VERSION ""

NS_ :

BS_:

BU_: mLEDR mLEDL TLR TLL RLR RLL HLR HLL DASCU CGW BCM

BO_ 656 DASCU_HLL_Object: 64 DASCU
 SG_ DAS_LeftObj_10_Z_2_Val : 337|7@1+ (1,0) [0|81] ""  mLEDL
 SG_ DAS_LeftObj_3_Y_1_Val : 88|9@1+ (1,0) [0|321] ""  mLEDL
 SG_ DAS_ADBLeftLED8_Req : 11|1@1+ (1,0) [0|1] ""  HLL
 SG_ DAS_ADBLeftLED11_Req : 14|1@1+ (1,0) [0|1] ""  HLL
 SG_ DAS_LeftObj_3_Y_2_Val : 104|9@1+ (1,0) [0|321] ""  mLEDL
 SG_ DAS_ADBLeftLED6_Req : 9|1@1+ (1,0) [0|1] ""  HLL
 SG_ DAS_LeftObj_6_Y_1_Val : 184|9@1+ (1,0) [0|321] ""  mLEDL
 SG_ DAS_LeftObj_5_Z_2_Val : 177|7@1+ (1,0) [0|81] ""  mLEDL
 SG_ DAS_LeftObj_9_Z_2_Val : 305|7@1+ (1,0) [0|81] ""  mLEDL
 SG_ DAS_LeftObj_5_Y_1_Val : 152|9@1+ (1,0) [0|321] ""  mLEDL
 SG_ DAS_LeftObj_1_Y_2_Val : 40|9@1+ (1,0) [0|321] ""  mLEDL
 SG_ DAS_LeftObj_2_Z_1_Val : 65|7@1+ (1,0) [0|81] ""  mLEDL
 SG_ DAS_LeftObj_1_Z_2_Val : 49|7@1+ (1,0) [0|81] ""  mLEDL
 SG_ DAS_ADBLeftLED13_Req : 16|1@1+ (1,0) [0|1] ""  HLL
 SG_ DAS_LeftObj_9_Y_2_Val : 296|9@1+ (1,0) [0|321] ""  mLEDL
 SG_ DAS_LeftObj_6_Z_2_Val : 209|7@1+ (1,0) [0|81] ""  mLEDL
 SG_ DAS_LeftObj_7_Z_2_Val : 241|7@1+ (1,0) [0|81] ""  mLEDL
 SG_ DAS_LeftObj_6_Z_1_Val : 193|7@1+ (1,0) [0|81] ""  mLEDL
 SG_ DAS_ADBLeftLED14_Req : 17|1@1+ (1,0) [0|1] ""  HLL
 SG_ DAS_LeftObj_5_Y_2_Val : 168|9@1+ (1,0) [0|321] ""  mLEDL
 SG_ DAS_LeftObj_7_Z_1_Val : 225|7@1+ (1,0) [0|81] ""  mLEDL
 SG_ DAS_ADBLeftLED2_Req : 5|1@1+ (1,0) [0|1] ""  HLL
 SG_ DAS_LeftObj_6_Y_2_Val : 200|9@1+ (1,0) [0|321] ""  mLEDL
 SG_ DAS_LeftObj_3_Z_2_Val : 113|7@1+ (1,0) [0|81] ""  mLEDL
 SG_ DAS_ADBLeftLED3_Req : 6|1@1+ (1,0) [0|1] ""  HLL
 SG_ DAS_ADBLeftLED10_Req : 13|1@1+ (1,0) [0|1] ""  HLL
 SG_ DAS_LeftObj_10_Z_1_Val : 321|7@1+ (1,0) [0|81] ""  mLEDL
 SG_ DAS_LeftObj_8_Z_2_Val : 273|7@1+ (1,0) [0|81] ""  mLEDL
 SG_ DAS_ADBLeftLED15_Req : 18|1@1+ (1,0) [0|1] ""  HLL
 SG_ DAS_LeftObj_4_Z_2_Val : 145|7@1+ (1,0) [0|81] ""  mLEDL
 SG_ DAS_ADBLeftLED1_Req : 4|1@1+ (1,0) [0|1] ""  HLL
 SG_ DAS_ADBLeftLED16_Req : 19|1@1+ (1,0) [0|1] ""  HLL
 SG_ DAS_LeftObj_7_Y_2_Val : 232|9@1+ (1,0) [0|321] ""  mLEDL
 SG_ DAS_LeftObj_2_Y_2_Val : 72|9@1+ (1,0) [0|321] ""  mLEDL
 SG_ DAS_LeftObj_10_Y_2_Val : 328|9@1+ (1,0) [0|321] ""  mLEDL
 SG_ DAS_LeftObj_8_Z_1_Val : 257|7@1+ (1,0) [0|81] ""  mLEDL
 SG_ DAS_LeftObj_9_Y_1_Val : 280|9@1+ (1,0) [0|321] ""  mLEDL
 SG_ DAS_LeftObj_8_Y_2_Val : 264|9@1+ (1,0) [0|321] ""  mLEDL
 SG_ DAS_LeftObj_4_Z_1_Val : 129|7@1+ (1,0) [0|81] ""  mLEDL
 SG_ DAS_LeftObj_2_Z_2_Val : 81|7@1+ (1,0) [0|81] ""  mLEDL
 SG_ DAS_LeftObj_8_Y_1_Val : 248|9@1+ (1,0) [0|321] ""  mLEDL
 SG_ DAS_LeftObj_1_Y_1_Val : 24|9@1+ (1,0) [0|511] ""  mLEDL
 SG_ DAS_LeftObj_4_Y_2_Val : 136|9@1+ (1,0) [0|321] ""  mLEDL
 SG_ DAS_LeftObj_4_Y_1_Val : 120|9@1+ (1,0) [0|321] ""  mLEDL
 SG_ DAS_ADBLeftLED5_Req : 8|1@1+ (1,0) [0|1] ""  HLL
 SG_ DAS_ADBLeftLED7_Req : 10|1@1+ (1,0) [0|1] ""  HLL
 SG_ DAS_LeftObj_5_Z_1_Val : 161|7@1+ (1,0) [0|81] ""  mLEDL
 SG_ DAS_LeftObj_10_Y_1_Val : 312|9@1+ (1,0) [0|321] ""  mLEDL
 SG_ DAS_ADBLeftLED12_Req : 15|1@1+ (1,0) [0|1] ""  HLL
 SG_ DAS_HLL_Object_RC : 379|4@1+ (1,0) [0|15] ""  mLEDL,HLL
 SG_ DAS_ADBLeftLED18_Req : 21|1@1+ (1,0) [0|1] ""  HLL
 SG_ DAS_LeftObj_3_Z_1_Val : 97|7@1+ (1,0) [0|81] ""  mLEDL
 SG_ DAS_LeftObj_2_Y_1_Val : 56|9@1+ (1,0) [0|321] ""  mLEDL
 SG_ DAS_ADBLeftLED17_Req : 20|1@1+ (1,0) [0|1] ""  HLL
 SG_ DAS_LeftObj_9_Z_1_Val : 289|7@1+ (1,0) [0|81] ""  mLEDL
 SG_ DAS_HLL_Object_CS : 384|8@1+ (1,0) [0|255] ""  mLEDL,HLL
 SG_ DAS_LeftObj_1_Z_1_Val : 33|7@1+ (1,0) [0|81] ""  mLEDL
 SG_ DAS_ADBLeftLED9_Req : 12|1@1+ (1,0) [0|1] ""  HLL
 SG_ DAS_ADBLeftLED4_Req : 7|1@1+ (1,0) [0|1] ""  HLL
 SG_ DAS_LeftObj_7_Y_1_Val : 216|9@1+ (1,0) [0|321] ""  mLEDL

BO_ 785 CCU_Stat1: 8 CGW
 SG_ CCU_AirDirectionFR_Foot_Stat : 29|1@1+ (1,0) [0|1] "" Vector__XXX
 SG_ CCU_AirDirectionFR_Face_Stat : 28|1@1+ (1,0) [0|1] "" Vector__XXX
 SG_ CCU_AirDirectionFR_Def_Stat : 27|1@1+ (1,0) [0|1] "" Vector__XXX
 SG_ CCU_AirDirectionFL_Foot_Stat : 26|1@1+ (1,0) [0|1] "" Vector__XXX
 SG_ CCU_AirDirectionFL_Face_Stat : 25|1@1+ (1,0) [0|1] "" Vector__XXX
 SG_ CCU_AirDirectionRL_Foot_Stat : 15|1@1+ (1,0) [0|1] "" Vector__XXX
 SG_ CCU_ModeRL_Stat : 4|2@1+ (1,0) [0|2] "" Vector__XXX
 SG_ CCU_AutoModeRR_Stat : 19|3@1+ (1,0) [0|5] "" Vector__XXX
 SG_ CCU_AutoModeFR_Stat : 11|3@1+ (1,0) [0|5] "" Vector__XXX
 SG_ CCU_AirDirectionRR_Face_Stat : 22|1@1+ (1,0) [0|1] "" Vector__XXX
 SG_ CCU_ModeRR_Stat : 6|2@1+ (1,0) [0|2] "" Vector__XXX
 SG_ CCU_AirDirectionRR_Foot_Stat : 23|1@1+ (1,0) [0|1] "" Vector__XXX
 SG_ CCU_Recirculation_Stat : 30|2@1+ (1,0) [0|2] "" Vector__XXX
 SG_ CCU_AutoModeRL_Stat : 16|3@1+ (1,0) [0|5] "" Vector__XXX
 SG_ CCU_AirDirectionFL_Def_Stat : 24|1@1+ (1,0) [0|1] "" Vector__XXX
 SG_ CCU_AutoModeFL_Stat : 8|3@1+ (1,0) [0|5] "" Vector__XXX
 SG_ CCU_ModeFL_Stat : 0|2@1+ (1,0) [0|2] "" Vector__XXX
 SG_ CCU_ModeFR_Stat : 2|2@1+ (1,0) [0|2] "" Vector__XXX
 SG_ CCU_AirDirectionRL_Face_Stat : 14|1@1+ (1,0) [0|1] "" Vector__XXX
 SG_ CCU_TargetTempFR_Stat : 43|5@1+ (0.5,16) [16|31.5] ""  DASCU
 SG_ CCU_BlowerSpeedRL_Stat : 48|3@1+ (1,0) [0|7] ""  DASCU
 SG_ CCU_BlowerSpeedFR_Stat : 40|3@1+ (1,0) [0|7] ""  DASCU
 SG_ CCU_TargetTempFL_Stat : 35|5@1+ (0.5,16) [16|31.5] ""  DASCU
 SG_ CCU_TargetTempRL_Stat : 59|5@1+ (0.5,16) [16|31.5] ""  DASCU
 SG_ CCU_BlowerSpeedFL_Stat : 32|3@1+ (1,0) [0|7] ""  DASCU
 SG_ CCU_TargetTempRR_Stat : 51|5@1+ (0.5,16) [16|31.5] ""  DASCU
 SG_ CCU_BlowerSpeedRR_Stat : 56|3@1+ (1,0) [0|7] ""  DASCU

BO_ 560 BCM_EXT_LGT: 8 BCM
 SG_ BCM_TargetLvlALS_Req : 32|8@1+ (1,0) [0|255] ""  HLL,HLR,DASCU
 SG_ BCM_CorneringLight_Req : 12|2@1+ (1,0) [0|3] ""  HLL,HLR
 SG_ BCM_RearFogLightCntrl_Req : 5|1@1+ (1,0) [0|1] ""  TLR,RLL,RLR,TLL
 SG_ BCM_PositionLightRear_Req : 1|1@1+ (1,0) [0|1] ""  TLL,RLL,RLR,TLR
 SG_ BCM_HighBeam_Req : 10|2@1+ (1,0) [0|3] ""  DASCU,mLEDL,HLR,HLL,mLEDR
 SG_ BCM_ELSStat_Req : 9|1@1+ (1,0) [0|1] ""  HLR,HLL,mLEDL,RLR,RLL,TLR,TLL,mLEDR
 SG_ BCM_ReverseLightCntrl_Req : 7|1@1+ (1,0) [0|1] ""  RLL,RLR,TLL,TLR
 SG_ BCM_EXT_LGT_RC : 52|4@1+ (1,0) [0|15] ""  TLR,mLEDR,TLL,mLEDL,HLR,RLR,HLL,DASCU,RLL
 SG_ BCM_CourtesyLightEffect_Req : 14|2@1+ (1,0) [0|2] ""  RLL,RLR,HLL,TLR,TLL,HLR
 SG_ BCM_TurnIndL_Req : 2|1@1+ (1,0) [0|1] ""  DASCU,RLL,HLL,TLL
 SG_ BCM_TrafficSide_Req : 8|1@1+ (1,0) [0|1] ""  HLL,HLR,mLEDR,mLEDL
 SG_ BCM_CourtesyProjAnimation_Req : 16|2@1+ (1,0) [0|3] ""  mLEDL,mLEDR
 SG_ BCM_EXT_LGT_CS : 56|8@1+ (1,0) [0|255] ""  TLL,RLL,mLEDR,RLR,mLEDL,DASCU,TLR,HLR,HLL
 SG_ BCM_DayRunningLight_Req : 4|1@1+ (1,0) [0|1] ""  HLL,HLR
 SG_ BCM_LowBeam_Req : 18|3@1+ (1,0) [0|4] ""  HLL,mLEDR,mLEDL,HLR
 SG_ BCM_PositionLightFront_Req : 0|1@1+ (1,0) [0|1] ""  HLR,HLL
 SG_ BCM_SteeringWheelAngle_Val : 24|8@1+ (1,0) [0|40] "°"  mLEDL,mLEDR
 SG_ BCM_BrakeLightCntrl_Req : 6|1@1+ (1,0) [0|1] ""  RLR,TLR,TLL,RLL
 SG_ BCM_TurnIndR_Req : 3|1@1+ (1,0) [0|1] ""  DASCU,TLR,HLR,RLR
 SG_ BCM_MLIA_Start_Req : 23|1@1+ (1,0) [0|1] ""  DASCU
 SG_ BCM_Proj_Start_Req : 21|2@1+ (1,0) [0|1] ""  DASCU

BO_ 1306 VEH_VIN: 8 CGW
 SG_ VIN_Char13 m1 : 48|8@1+ (1,0) [0|255] "" Vector__XXX
 SG_ VIN_Char1 m0 : 8|8@1+ (1,0) [0|255] "" Vector__XXX
 SG_ VIN_Char3 m0 : 24|8@1+ (1,0) [0|255] "" Vector__XXX
 SG_ VIN_Char17 m2 : 24|8@1+ (1,0) [0|255] "" Vector__XXX
 SG_ VIN_Char7 m0 : 56|8@1+ (1,0) [0|255] "" Vector__XXX
 SG_ VIN_Char10 m1 : 24|8@1+ (1,0) [0|255] "" Vector__XXX
 SG_ VIN_Char12 m1 : 40|8@1+ (1,0) [0|255] "" Vector__XXX
 SG_ VIN_Addressing M : 0|2@1+ (1,0) [0|2] "" Vector__XXX
 SG_ VIN_Char5 m0 : 40|8@1+ (1,0) [0|255] "" Vector__XXX
 SG_ VIN_Char9 m1 : 16|8@1+ (1,0) [0|255] "" Vector__XXX
 SG_ VIN_Char2 m0 : 16|8@1+ (1,0) [0|255] "" Vector__XXX
 SG_ VIN_Char4 m0 : 32|8@1+ (1,0) [0|255] "" Vector__XXX
 SG_ VIN_Char15 m2 : 8|8@1+ (1,0) [0|255] "" Vector__XXX
 SG_ VIN_Char6 m0 : 48|8@1+ (1,0) [0|255] "" Vector__XXX
 SG_ VIN_Char8 m1 : 8|8@1+ (1,0) [0|255] "" Vector__XXX
 SG_ VIN_Char11 m1 : 32|8@1+ (1,0) [0|255] "" Vector__XXX
 SG_ VIN_Char14 m1 : 56|8@1+ (1,0) [0|255] "" Vector__XXX
 SG_ VIN_Char16 m2 : 16|8@1+ (1,0) [0|255] "" Vector__XXX

BO_ 1980 Diag_To_ERAG: 8 DASCU
 SG_ Diag_To_ERAG_Sig : 7|64@0+ (1,0) [0|1.84467440737096E+019] ""  CGW

BO_ 2005 Diag_To_DASCU: 8 CGW
 SG_ Diag_To_DASCU_Sig : 7|64@0+ (1,0) [0|1.84467440737096E+019] ""  DASCU

BO_ 1964 Diag_From_ERAG: 8 CGW
 SG_ Diag_From_ERAG_Sig : 7|64@0+ (1,0) [0|1.84467440737096E+019] ""  DASCU

BO_ 1989 Diag_From_DASCU: 8 DASCU
 SG_ Diag_From_DASCU_Sig : 7|64@0+ (1,0) [0|1.84467440737096E+019] ""  CGW

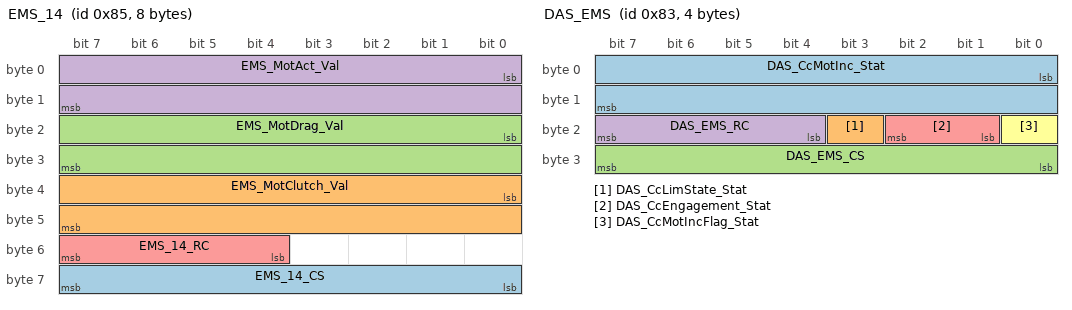
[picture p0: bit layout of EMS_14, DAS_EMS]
BO_ 133 EMS_14: 8 CGW
 SG_ EMS_14_CS : 56|8@1+ (1,0) [0|255] ""  DASCU
 SG_ EMS_MotClutch_Val : 32|16@1+ (1,-30000) [-30000|30000] "Nm"  DASCU
 SG_ EMS_MotDrag_Val : 16|16@1+ (1,-30000) [-30000|30000] "Nm"  DASCU
 SG_ EMS_MotAct_Val : 0|16@1+ (1,-30000) [-30000|30000] "Nm"  DASCU
 SG_ EMS_14_RC : 52|4@1+ (1,0) [0|15] ""  DASCU

BO_ 131 DAS_EMS: 4 DASCU
 SG_ DAS_CcMotInc_Stat : 0|16@1+ (1,-30000) [-30000|30000] ""  CGW
 SG_ DAS_CcLimState_Stat : 19|1@1+ (1,0) [0|1] ""  CGW
 SG_ DAS_EMS_CS : 24|8@1+ (1,0) [0|255] ""  CGW
 SG_ DAS_EMS_RC : 20|4@1+ (1,0) [0|15] ""  CGW
 SG_ DAS_CcEngagement_Stat : 17|2@1+ (1,0) [0|3] ""  CGW
 SG_ DAS_CcMotIncFlag_Stat : 16|1@1+ (1,0) [0|1] ""  CGW

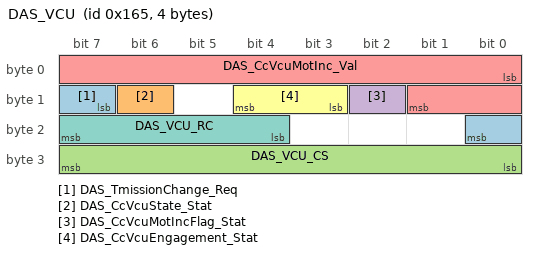
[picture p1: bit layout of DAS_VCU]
BO_ 357 DAS_VCU: 4 DASCU
 SG_ DAS_TmissionChange_Req : 15|2@1+ (1,0) [0|3] ""  CGW
 SG_ DAS_CcVcuState_Stat : 14|1@1+ (1,0) [0|1] ""  CGW
 SG_ DAS_VCU_CS : 24|8@1+ (1,0) [0|255] ""  CGW
 SG_ DAS_CcVcuMotIncFlag_Stat : 10|1@1+ (1,0) [0|1] ""  CGW
 SG_ DAS_CcVcuMotInc_Val : 0|10@1+ (1,0) [0|1000] ""  CGW
 SG_ DAS_CcVcuEngagement_Stat : 11|2@1+ (1,0) [0|3] ""  CGW
 SG_ DAS_VCU_RC : 20|4@1+ (1,0) [0|15] ""  CGW

CM_ SG_ 656 DAS_LeftObj_10_Z_2_Val "Object_10 Vertical  Value_2";
CM_ SG_ 656 DAS_LeftObj_3_Y_1_Val "Object_3 Horizontal Value_1";
CM_ SG_ 656 DAS_ADBLeftLED8_Req "Left_ADB LED#8 Control Signal";
CM_ SG_ 656 DAS_ADBLeftLED11_Req "Left_ADB LED#11 Control Signal";
CM_ SG_ 656 DAS_LeftObj_3_Y_2_Val "Object_3 Horizontal Value_2";
CM_ SG_ 656 DAS_ADBLeftLED6_Req "Left_ADB LED#6 Control Signal";
CM_ SG_ 656 DAS_LeftObj_6_Y_1_Val "Object_6 Horizontal Value_1";
CM_ SG_ 656 DAS_LeftObj_5_Z_2_Val "Object_5 Vertical  Value_2";
CM_ SG_ 656 DAS_LeftObj_9_Z_2_Val "Object_9 Vertical  Value_2";
CM_ SG_ 656 DAS_LeftObj_5_Y_1_Val "Object_5 Horizontal Value_1";
CM_ SG_ 656 DAS_LeftObj_1_Y_2_Val "Object_1 Horizontal Value_2";
CM_ SG_ 656 DAS_LeftObj_2_Z_1_Val "Object_2 Vertical Value_1";
CM_ SG_ 656 DAS_LeftObj_1_Z_2_Val "Object_1 Vertical  Value_2";
CM_ SG_ 656 DAS_ADBLeftLED13_Req "Left_ADB LED#13 Control Signal";
CM_ SG_ 656 DAS_LeftObj_9_Y_2_Val "Object_9 Horizontal Value_2";
CM_ SG_ 656 DAS_LeftObj_6_Z_2_Val "Object_6 Vertical  Value_2";
CM_ SG_ 656 DAS_LeftObj_7_Z_2_Val "Object_7 Vertical  Value_2";
CM_ SG_ 656 DAS_LeftObj_6_Z_1_Val "Object_6 Vertical Value_1";
CM_ SG_ 656 DAS_ADBLeftLED14_Req "Left_ADB LED#14 Control Signal";
CM_ SG_ 656 DAS_LeftObj_5_Y_2_Val "Object_5 Horizontal Value_2";
CM_ SG_ 656 DAS_LeftObj_7_Z_1_Val "Object_7 Vertical Value_1";
CM_ SG_ 656 DAS_ADBLeftLED2_Req "Left_ADB LED#2 Control Signal";
CM_ SG_ 656 DAS_LeftObj_6_Y_2_Val "Object_6 Horizontal Value_2";
CM_ SG_ 656 DAS_LeftObj_3_Z_2_Val "Object_3 Vertical  Value_2";
CM_ SG_ 656 DAS_ADBLeftLED3_Req "Left_ADB LED#3 Control Signal";
CM_ SG_ 656 DAS_ADBLeftLED10_Req "Left_ADB LED#10 Control Signal";
CM_ SG_ 656 DAS_LeftObj_10_Z_1_Val "Object_10 Vertical Value_1";
CM_ SG_ 656 DAS_LeftObj_8_Z_2_Val "Object_8 Vertical  Value_2";
CM_ SG_ 656 DAS_ADBLeftLED15_Req "Left_ADB LED#15 Control Signal";
CM_ SG_ 656 DAS_LeftObj_4_Z_2_Val "Object_4 Vertical  Value_2";
CM_ SG_ 656 DAS_ADBLeftLED1_Req "Left_ADB LED#1 Control Signal";
CM_ SG_ 656 DAS_ADBLeftLED16_Req "Left_ADB LED#16 Control Signal";
CM_ SG_ 656 DAS_LeftObj_7_Y_2_Val "Object_7 Horizontal Value_2";
CM_ SG_ 656 DAS_LeftObj_2_Y_2_Val "Object_2 Horizontal Value_2";
CM_ SG_ 656 DAS_LeftObj_10_Y_2_Val "Object_10 Horizontal Value_2";
CM_ SG_ 656 DAS_LeftObj_8_Z_1_Val "Object_8 Vertical Value_1";
CM_ SG_ 656 DAS_LeftObj_9_Y_1_Val "Object_9 Horizontal Value_1";
CM_ SG_ 656 DAS_LeftObj_8_Y_2_Val "Object_8 Horizontal Value_2";
CM_ SG_ 656 DAS_LeftObj_4_Z_1_Val "Object_4 Vertical Value_1";
CM_ SG_ 656 DAS_LeftObj_2_Z_2_Val "Object_2 Vertical  Value_2";
CM_ SG_ 656 DAS_LeftObj_8_Y_1_Val "Object_8 Horizontal Value_1";
CM_ SG_ 656 DAS_LeftObj_1_Y_1_Val "Object_1 Horizontal Value_1";
CM_ SG_ 656 DAS_LeftObj_4_Y_2_Val "Object_4 Horizontal Value_2";
CM_ SG_ 656 DAS_LeftObj_4_Y_1_Val "Object_4 Horizontal Value_1";
CM_ SG_ 656 DAS_ADBLeftLED5_Req "Left_ADB LED#5 Control Signal";
CM_ SG_ 656 DAS_ADBLeftLED7_Req "Left_ADB LED#7 Control Signal";
CM_ SG_ 656 DAS_LeftObj_5_Z_1_Val "Object_5 Vertical Value_1";
CM_ SG_ 656 DAS_LeftObj_10_Y_1_Val "Object_10 Horizontal Value_1";
CM_ SG_ 656 DAS_ADBLeftLED12_Req "Left_ADB LED#12 Control Signal";
CM_ SG_ 656 DAS_HLL_Object_RC "Rolling Counter [0 - 15]";
CM_ SG_ 656 DAS_ADBLeftLED18_Req "Left_ADB LED#18 Control Signal";
CM_ SG_ 656 DAS_LeftObj_3_Z_1_Val "Object_3 Vertical Value_1";
CM_ SG_ 656 DAS_LeftObj_2_Y_1_Val "Object_2 Horizontal Value_1";
CM_ SG_ 656 DAS_ADBLeftLED17_Req "Left_ADB LED#17 Control Signal";
CM_ SG_ 656 DAS_LeftObj_9_Z_1_Val "Object_9 Vertical Value_1";
CM_ SG_ 656 DAS_HLL_Object_CS "Checksum XOR8 of the data field this message
Checksum computed as per XOR algorithm:
Byte 1 XOR byte 2 .... XOR byte n-1. (n = packet length.)";
CM_ SG_ 656 DAS_LeftObj_1_Z_1_Val "Object_1 Vertical Value_1";
CM_ SG_ 656 DAS_ADBLeftLED9_Req "Left_ADB LED#9 Control Signal";
CM_ SG_ 656 DAS_ADBLeftLED4_Req "Left_ADB LED#4 Control Signal";
CM_ SG_ 656 DAS_LeftObj_7_Y_1_Val "Object_7 Horizontal Value_1";
CM_ SG_ 785 CCU_AirDirectionFR_Foot_Stat "Airflow direction mode for front right zone status";
CM_ SG_ 785 CCU_AirDirectionFR_Face_Stat "Airflow direction mode for front right zone status";
CM_ SG_ 785 CCU_AirDirectionFR_Def_Stat "Airflow direction mode for front right zone status";
CM_ SG_ 785 CCU_AirDirectionFL_Foot_Stat "Airflow direction mode for front left zone status";
CM_ SG_ 785 CCU_AirDirectionFL_Face_Stat "Airflow direction mode for front left zone status";
CM_ SG_ 785 CCU_AirDirectionRL_Foot_Stat "Airflow direction mode for rear left zone status";
CM_ SG_ 785 CCU_ModeRL_Stat "Climate control mode for rear left zone status";
CM_ SG_ 785 CCU_AutoModeRR_Stat "Climate control auto mode for rear right zone status";
CM_ SG_ 785 CCU_AutoModeFR_Stat "Climate control auto mode for front right zone status";
CM_ SG_ 785 CCU_AirDirectionRR_Face_Stat "Airflow direction mode for rear right zone status";
CM_ SG_ 785 CCU_ModeRR_Stat "Climate control mode for rear right zone status";
CM_ SG_ 785 CCU_AirDirectionRR_Foot_Stat "Airflow direction mode for rear right zone status";
CM_ SG_ 785 CCU_Recirculation_Stat "Recirculation mode status";
CM_ SG_ 785 CCU_AutoModeRL_Stat "Climate control auto mode for rear left zone status";
CM_ SG_ 785 CCU_AirDirectionFL_Def_Stat "Airflow direction mode for front left zone status";
CM_ SG_ 785 CCU_AutoModeFL_Stat "Climate control auto mode for front left zone status";
CM_ SG_ 785 CCU_ModeFL_Stat "Climate control mode for front left zone status";
CM_ SG_ 785 CCU_ModeFR_Stat "Climate control mode for front right zone status";
CM_ SG_ 785 CCU_AirDirectionRL_Face_Stat "Airflow direction mode for rear left zone status";
CM_ SG_ 785 CCU_TargetTempFR_Stat "Target temperature for front right zone status";
CM_ SG_ 785 CCU_BlowerSpeedRL_Stat "Blower speed for rear left zone status";
CM_ SG_ 785 CCU_BlowerSpeedFR_Stat "Blower speed for front right zone status";
CM_ SG_ 785 CCU_TargetTempFL_Stat "Target temperature for front left zone status";
CM_ SG_ 785 CCU_TargetTempRL_Stat "Target temperature for rear left zone status";
CM_ SG_ 785 CCU_BlowerSpeedFL_Stat "Blower speed for front left zone status";
CM_ SG_ 785 CCU_TargetTempRR_Stat "Target temperature for rear right zone status";
CM_ SG_ 785 CCU_BlowerSpeedRR_Stat "Blower speed for rear right zone status";
CM_ SG_ 560 BCM_TargetLvlALS_Req "Target Value for HeadLights Level from AutoLeveling System";
CM_ SG_ 560 BCM_CorneringLight_Req "Cornering Light Control Signal";
CM_ SG_ 560 BCM_RearFogLightCntrl_Req "Rear Fog Light Control Signal";
CM_ SG_ 560 BCM_PositionLightRear_Req "Rear Position Light Control Signal";
CM_ SG_ 560 BCM_HighBeam_Req "High Beam Control Signal";
CM_ SG_ 560 BCM_ELSStat_Req "Exterior Light Terminal ";
CM_ SG_ 560 BCM_ReverseLightCntrl_Req "Reverse Light Control Signal";
CM_ SG_ 560 BCM_EXT_LGT_RC "Rolling Counter [0 - 15]";
CM_ SG_ 560 BCM_CourtesyLightEffect_Req "Welcome/Leaving Light Effect Control Signal";
CM_ SG_ 560 BCM_TurnIndL_Req "Left Direction Indicator Control Signal";
CM_ SG_ 560 BCM_TrafficSide_Req "Travel Light Control Signal";
CM_ SG_ 560 BCM_CourtesyProjAnimation_Req "Projection Animation Control Signal";
CM_ SG_ 560 BCM_EXT_LGT_CS "Checksum XOR8 of the data field this message
Checksum computed as per XOR algorithm:
Byte 1 XOR byte 2 .... XOR byte n-1. (n = packet length.)";
CM_ SG_ 560 BCM_DayRunningLight_Req "Daytime Running Light Control Signal";
CM_ SG_ 560 BCM_LowBeam_Req "Low Beam Control Signal";
CM_ SG_ 560 BCM_PositionLightFront_Req "Front Position Light Control Signal";
CM_ SG_ 560 BCM_SteeringWheelAngle_Val "Angle of Steering Wheel Rotation";
CM_ SG_ 560 BCM_BrakeLightCntrl_Req "Brake Light Control Signal";
CM_ SG_ 560 BCM_TurnIndR_Req "Right Direction Indicator Control Signal";
CM_ SG_ 560 BCM_MLIA_Start_Req "Request for automatic high beam";
CM_ SG_ 560 BCM_Proj_Start_Req "Conditions for possibility an activation a project animation on the road";
CM_ BO_ 1306 "VIN Code structure:
e.g: XKN412300H1000027
XKN: code WMI
412300: vehicle model
H: Vehicle production year
1: assembling at NAMI
6 last characters: serial number.
REMARK: In case of VIN programming has failed, all characters will be = '0'
";
CM_ SG_ 1306 VIN_Char13 "VIN character 13
REMARK:
In case of VIN programming has failed, character will be = '0'";
CM_ SG_ 1306 VIN_Char1 "VIN character 1
REMARK:
In case of VIN programming has failed, character will be = '0'";
CM_ SG_ 1306 VIN_Char3 "VIN character 3
REMARK:
In case of VIN programming has failed, character will be = '0'";
CM_ SG_ 1306 VIN_Char17 "VIN character 17
REMARK:
In case of VIN programming has failed, character will be = '0'";
CM_ SG_ 1306 VIN_Char7 "VIN character 7
REMARK:
In case of VIN programming has failed, character will be = '0'";
CM_ SG_ 1306 VIN_Char10 "VIN character 10
REMARK:
In case of VIN programming has failed, character will be = '0'";
CM_ SG_ 1306 VIN_Char12 "VIN character 12
REMARK:
In case of VIN programming has failed, character will be = '0'";
CM_ SG_ 1306 VIN_Addressing "Addresses the VIN Part:
0x0 = Addresses VIN part 1
0x1 = Addresses VIN part 2
0x2 = Addresses VIN part 3";
CM_ SG_ 1306 VIN_Char5 "VIN character 5
REMARK:
In case of VIN programming has failed, character will be = '0'";
CM_ SG_ 1306 VIN_Char9 "VIN character 9
REMARK:
In case of VIN programming has failed, character will be = '0'";
CM_ SG_ 1306 VIN_Char2 "VIN character 2
REMARK:
In case of VIN programming has failed, character will be = '0'";
CM_ SG_ 1306 VIN_Char4 "VIN character 4
REMARK:
In case of VIN programming has failed, character will be = '0'";
CM_ SG_ 1306 VIN_Char15 "VIN character 15
REMARK:
In case of VIN programming has failed, character will be = '0'";
CM_ SG_ 1306 VIN_Char6 "VIN character 6
REMARK:
In case of VIN programming has failed, character will be = '0'";
CM_ SG_ 1306 VIN_Char8 "VIN character 8
REMARK:
In case of VIN programming has failed, character will be = '0'";
CM_ SG_ 1306 VIN_Char11 "VIN character 11
REMARK:
In case of VIN programming has failed, character will be = '0'";
CM_ SG_ 1306 VIN_Char14 "VIN character 14
REMARK:
In case of VIN programming has failed, character will be = '0'";
CM_ SG_ 1306 VIN_Char16 "VIN character 16
REMARK:
In case of VIN programming has failed, character will be = '0'";
CM_ BO_ 1980 "Diagnostic Message";
CM_ SG_ 1980 Diag_To_ERAG_Sig "Diagnostic signal";
CM_ BO_ 2005 "Diagnostic Message";
CM_ SG_ 2005 Diag_To_DASCU_Sig "Diagnostic signal";
CM_ BO_ 1964 "Diagnostic Message";
CM_ SG_ 1964 Diag_From_ERAG_Sig "Diagnostic signal";
CM_ BO_ 1989 "Diagnostic Message";
CM_ SG_ 1989 Diag_From_DASCU_Sig "Diagnostic signal";
CM_ SG_ 133 EMS_14_CS "Checksum CRC8 SAE J1850 of the data field this message";
CM_ SG_ 133 EMS_MotClutch_Val "Torque at the clutch";
CM_ SG_ 133 EMS_MotDrag_Val "Current virtual engine (combustion engine+e-machine) torque losses";
CM_ SG_ 133 EMS_MotAct_Val "Current virtual engine (combustion engine+ e-machine) torque, including all the losses";
CM_ SG_ 133 EMS_14_RC "Rolling Counter [0 - 15]";
CM_ SG_ 131 DAS_CcMotInc_Stat "Target total torque on engine";
CM_ SG_ 131 DAS_CcLimState_Stat "Request from the limiter";
CM_ SG_ 131 DAS_EMS_CS "Checksum CRC8 SAE J1850 of the data field this message";
CM_ SG_ 131 DAS_EMS_RC "Rolling Counter [0 - 15]";
CM_ SG_ 131 DAS_CcEngagement_Stat "Type of CC";
CM_ SG_ 131 DAS_CcMotIncFlag_Stat "Engine torque increase request flag";
CM_ SG_ 357 DAS_TmissionChange_Req "Transmission mode change request";
CM_ SG_ 357 DAS_CcVcuState_Stat "Mode of CC";
CM_ SG_ 357 DAS_VCU_CS "Checksum CRC8 SAE J1850 of the data field this message";
CM_ SG_ 357 DAS_CcVcuMotIncFlag_Stat "Engine torque increase request flag";
CM_ SG_ 357 DAS_CcVcuMotInc_Val "Target total torque on engine";
CM_ SG_ 357 DAS_CcVcuEngagement_Stat "Type of CC";
CM_ SG_ 357 DAS_VCU_RC "Rolling Counter [0 - 15]";
BA_DEF_ SG_  "GenSigEVName" STRING ;
BA_DEF_ SG_  "SigType" ENUM  "Default","Range","RangeSigned","ASCII","Discrete","Control","ReferencePGN","DTC","StringDelimiter","StringLength","StringLengthControl","MessageCounter","MessageChecksum";
BA_DEF_ SG_  "GenSigILSupport" ENUM  "No","Yes";
BA_DEF_ SG_  "GenSigSendType" ENUM  "Cyclic","OnWrite","OnWriteWithRepetition","OnChange","OnChangeWithRepetition","IfActive","IfActiveWithRepetition","NoSigSendType","NotUsed","NotUsed","NotUsed","NotUsed","NotUsed";
BA_DEF_ SG_  "GenSigStartValue" INT 0 0;
BA_DEF_ BO_  "GenMsgRequestable" INT 0 1;
BA_DEF_ BO_  "GenMsgILSupport" ENUM  "No","Yes";
BA_DEF_ BO_  "VFrameFormat" ENUM  "StandardCAN","ExtendedCAN","reserved","J1939PG","reserved","reserved","reserved","reserved","reserved","reserved","reserved","reserved","reserved","reserved","StandardCAN_FD","ExtendedCAN_FD";
BA_DEF_ BO_  "J1939PgAppearanceOnBus" ENUM  "Default","CAN_Extended","CANFD_Extended";
BA_DEF_ BO_  "J1939CPgTOS" INT 0 7;
BA_DEF_ BO_  "J1939CPgSendTimeout" INT -1 3600000;
BA_DEF_ BO_  "DiagRequest" ENUM  "No","Yes";
BA_DEF_ BO_  "CANFD_BRS" ENUM  "0","1";
BA_DEF_ BO_  "GenMsgCycleTime" INT 0 0;
BA_DEF_ BO_  "GenMsgSendType" ENUM  "Cyclic","Spontaneous","IfActive","NoMsgSendType","NotUsed";
BA_DEF_DEF_  "GenSigEVName" "Env@Nodename_@Signame";
BA_DEF_DEF_  "SigType" "Default";
BA_DEF_DEF_  "GenSigILSupport" "Yes";
BA_DEF_DEF_  "GenSigSendType" "Cyclic";
BA_DEF_DEF_  "GenSigStartValue" 0;
BA_DEF_DEF_  "GenMsgRequestable" 1;
BA_DEF_DEF_  "GenMsgILSupport" "Yes";
BA_DEF_DEF_  "VFrameFormat" "";
BA_DEF_DEF_  "J1939PgAppearanceOnBus" "Default";
BA_DEF_DEF_  "J1939CPgTOS" 2;
BA_DEF_DEF_  "J1939CPgSendTimeout" -1;
BA_DEF_DEF_  "DiagRequest" "No";
BA_DEF_DEF_  "CANFD_BRS" "1";
BA_DEF_DEF_  "GenMsgCycleTime" 0;
BA_DEF_DEF_  "GenMsgSendType" "";
BA_ "GenMsgCycleTime" BO_ 656 50;
BA_ "GenMsgSendType" BO_ 656 0;
BA_ "VFrameFormat" BO_ 656 14;
BA_ "VFrameFormat" BO_ 785 0;
BA_ "GenMsgCycleTime" BO_ 785 100;
BA_ "GenMsgSendType" BO_ 785 0;
BA_ "VFrameFormat" BO_ 560 0;
BA_ "GenMsgCycleTime" BO_ 560 50;
BA_ "GenMsgSendType" BO_ 560 0;
BA_ "VFrameFormat" BO_ 1306 0;
BA_ "GenMsgCycleTime" BO_ 1306 5000;
BA_ "GenMsgSendType" BO_ 1306 0;
BA_ "VFrameFormat" BO_ 1980 0;
BA_ "GenMsgSendType" BO_ 1980 1;
BA_ "VFrameFormat" BO_ 2005 0;
BA_ "GenMsgSendType" BO_ 2005 1;
BA_ "VFrameFormat" BO_ 1964 0;
BA_ "GenMsgSendType" BO_ 1964 1;
BA_ "VFrameFormat" BO_ 1989 0;
BA_ "GenMsgSendType" BO_ 1989 1;
BA_ "VFrameFormat" BO_ 133 0;
BA_ "GenMsgCycleTime" BO_ 133 10;
BA_ "GenMsgSendType" BO_ 133 0;
BA_ "VFrameFormat" BO_ 131 0;
BA_ "GenMsgCycleTime" BO_ 131 20;
BA_ "GenMsgSendType" BO_ 131 0;
BA_ "VFrameFormat" BO_ 357 0;
BA_ "GenMsgCycleTime" BO_ 357 50;
BA_ "GenMsgSendType" BO_ 357 0;
BA_ "GenSigStartValue" SG_ 133 EMS_MotClutch_Val 30000;
BA_ "GenSigStartValue" SG_ 133 EMS_MotDrag_Val 30000;
BA_ "GenSigStartValue" SG_ 133 EMS_MotAct_Val 30000;
BA_ "GenSigStartValue" SG_ 131 DAS_CcMotInc_Stat 30000;
VAL_ 656 DAS_LeftObj_10_Z_2_Val 81 "Error" 80 "80" 79 "79" 78 "78" 77 "77" 76 "76" 75 "75" 74 "74" 73 "73" 72 "72" 71 "71" 70 "70" 69 "69" 68 "68" 67 "67" 66 "66" 65 "65" 64 "64" 63 "63" 62 "62" 61 "61" 60 "60" 59 "59" 58 "58" 57 "57" 56 "56" 55 "55" 54 "54" 53 "53" 52 "52" 51 "51" 50 "50" 49 "49" 48 "48" 47 "47" 46 "46" 45 "45" 44 "44" 43 "43" 42 "42" 41 "41" 40 "40" 39 "39" 38 "38" 37 "37" 36 "36" 35 "35" 34 "34" 33 "33" 32 "32" 31 "31" 30 "30" 29 "29" 28 "28" 27 "27" 26 "26" 25 "25" 24 "24" 23 "23" 22 "22" 21 "21" 20 "20" 19 "19" 18 "18" 17 "17" 16 "16" 15 "15" 14 "14" 13 "13" 12 "12" 11 "11" 10 "10" 9 "9" 8 "8" 7 "7" 6 "6" 5 "5" 4 "4" 3 "3" 2 "2" 1 "1" 0 "Unknown" ;
VAL_ 656 DAS_LeftObj_3_Y_1_Val 321 "Error" 320 "320" 319 "319" 318 "318" 317 "317" 316 "316" 315 "315" 314 "314" 313 "313" 312 "312" 311 "311" 310 "310" 309 "309" 308 "308" 307 "307" 306 "306" 305 "305" 304 "304" 303 "303" 302 "302" 301 "301" 300 "300" 299 "299" 298 "298" 297 "297" 296 "296" 295 "295" 294 "294" 293 "293" 292 "292" 291 "291" 290 "290" 289 "289" 288 "288" 287 "287" 286 "286" 285 "285" 284 "284" 283 "283" 282 "282" 281 "281" 280 "280" 279 "279" 278 "278" 277 "277" 276 "276" 275 "275" 274 "274" 273 "273" 272 "272" 271 "271" 270 "270" 269 "269" 268 "268" 267 "267" 266 "266" 265 "265" 264 "264" 263 "263" 262 "262" 261 "261" 260 "260" 259 "259" 258 "258" 257 "257" 256 "256" 255 "255" 254 "254" 253 "253" 252 "252" 251 "251" 250 "250" 249 "249" 248 "248" 247 "247" 246 "246" 245 "245" 244 "244" 243 "243" 242 "242" 241 "241" 240 "240" 239 "239" 238 "238" 237 "237" 236 "236" 235 "235" 234 "234" 233 "233" 232 "232" 231 "231" 230 "230" 229 "229" 228 "228" 227 "227" 226 "226" 225 "225" 224 "224" 223 "223" 222 "222" 221 "221" 220 "220" 219 "219" 218 "218" 217 "217" 216 "216" 215 "215" 214 "214" 213 "213" 212 "212" 211 "211" 210 "210" 209 "209" 208 "208" 207 "207" 206 "206" 205 "205" 204 "204" 203 "203" 202 "202" 201 "201" 200 "200" 199 "199" 198 "198" 197 "197" 196 "196" 195 "195" 194 "194" 193 "193" 192 "192" 191 "191" 190 "190" 189 "189" 188 "188" 187 "187" 186 "186" 185 "185" 184 "184" 183 "183" 182 "182" 181 "181" 180 "180" 179 "179" 178 "178" 177 "177" 176 "176" 175 "175" 174 "174" 173 "173" 172 "172" 171 "171" 170 "170" 169 "169" 168 "168" 167 "167" 166 "166" 165 "165" 164 "164" 163 "163" 162 "162" 161 "161" 160 "160" 159 "159" 158 "158" 157 "157" 156 "156" 155 "155" 154 "154" 153 "153" 152 "152" 151 "151" 150 "150" 149 "149" 148 "148" 147 "147" 146 "146" 145 "145" 144 "144" 143 "143" 142 "142" 141 "141" 140 "140" 139 "139" 138 "138" 137 "137" 136 "136" 135 "135" 134 "134" 133 "133" 132 "132" 131 "131" 130 "130" 129 "129" 128 "128" 127 "127" 126 "126" 125 "125" 124 "124" 123 "123" 122 "122" 121 "121" 120 "120" 119 "119" 118 "118" 117 "117" 116 "116" 115 "115" 114 "114" 113 "113" 112 "112" 111 "111" 110 "110" 109 "109" 108 "108" 107 "107" 106 "106" 105 "105" 104 "104" 103 "103" 102 "102" 101 "101" 100 "100" 99 "99" 98 "98" 97 "97" 96 "96" 95 "95" 94 "94" 93 "93" 92 "92" 91 "91" 90 "90" 89 "89" 88 "88" 87 "87" 86 "86" 85 "85" 84 "84" 83 "83" 82 "82" 81 "81" 80 "80" 79 "79" 78 "78" 77 "77" 76 "76" 75 "75" 74 "74" 73 "73" 72 "72" 71 "71" 70 "70" 69 "69" 68 "68" 67 "67" 66 "66" 65 "65" 64 "64" 63 "63" 62 "62" 61 "61" 60 "60" 59 "59" 58 "58" 57 "57" 56 "56" 55 "55" 54 "54" 53 "53" 52 "52" 51 "51" 50 "50" 49 "49" 48 "48" 47 "47" 46 "46" 45 "45" 44 "44" 43 "43" 42 "42" 41 "41" 40 "40" 39 "39" 38 "38" 37 "37" 36 "36" 35 "35" 34 "34" 33 "33" 32 "32" 31 "31" 30 "30" 29 "29" 28 "28" 27 "27" 26 "26" 25 "25" 24 "24" 23 "23" 22 "22" 21 "21" 20 "20" 19 "19" 18 "18" 17 "17" 16 "16" 15 "15" 14 "14" 13 "13" 12 "12" 11 "11" 10 "10" 9 "9" 8 "8" 7 "7" 6 "6" 5 "5" 4 "4" 3 "3" 2 "2" 1 "1" 0 "Unknown" ;
VAL_ 656 DAS_ADBLeftLED8_Req 1 "On" 0 "Off" ;
VAL_ 656 DAS_ADBLeftLED11_Req 1 "On" 0 "Off" ;
VAL_ 656 DAS_LeftObj_3_Y_2_Val 321 "Error" 320 "320" 319 "319" 318 "318" 317 "317" 316 "316" 315 "315" 314 "314" 313 "313" 312 "312" 311 "311" 310 "310" 309 "309" 308 "308" 307 "307" 306 "306" 305 "305" 304 "304" 303 "303" 302 "302" 301 "301" 300 "300" 299 "299" 298 "298" 297 "297" 296 "296" 295 "295" 294 "294" 293 "293" 292 "292" 291 "291" 290 "290" 289 "289" 288 "288" 287 "287" 286 "286" 285 "285" 284 "284" 283 "283" 282 "282" 281 "281" 280 "280" 279 "279" 278 "278" 277 "277" 276 "276" 275 "275" 274 "274" 273 "273" 272 "272" 271 "271" 270 "270" 269 "269" 268 "268" 267 "267" 266 "266" 265 "265" 264 "264" 263 "263" 262 "262" 261 "261" 260 "260" 259 "259" 258 "258" 257 "257" 256 "256" 255 "255" 254 "254" 253 "253" 252 "252" 251 "251" 250 "250" 249 "249" 248 "248" 247 "247" 246 "246" 245 "245" 244 "244" 243 "243" 242 "242" 241 "241" 240 "240" 239 "239" 238 "238" 237 "237" 236 "236" 235 "235" 234 "234" 233 "233" 232 "232" 231 "231" 230 "230" 229 "229" 228 "228" 227 "227" 226 "226" 225 "225" 224 "224" 223 "223" 222 "222" 221 "221" 220 "220" 219 "219" 218 "218" 217 "217" 216 "216" 215 "215" 214 "214" 213 "213" 212 "212" 211 "211" 210 "210" 209 "209" 208 "208" 207 "207" 206 "206" 205 "205" 204 "204" 203 "203" 202 "202" 201 "201" 200 "200" 199 "199" 198 "198" 197 "197" 196 "196" 195 "195" 194 "194" 193 "193" 192 "192" 191 "191" 190 "190" 189 "189" 188 "188" 187 "187" 186 "186" 185 "185" 184 "184" 183 "183" 182 "182" 181 "181" 180 "180" 179 "179" 178 "178" 177 "177" 176 "176" 175 "175" 174 "174" 173 "173" 172 "172" 171 "171" 170 "170" 169 "169" 168 "168" 167 "167" 166 "166" 165 "165" 164 "164" 163 "163" 162 "162" 161 "161" 160 "160" 159 "159" 158 "158" 157 "157" 156 "156" 155 "155" 154 "154" 153 "153" 152 "152" 151 "151" 150 "150" 149 "149" 148 "148" 147 "147" 146 "146" 145 "145" 144 "144" 143 "143" 142 "142" 141 "141" 140 "140" 139 "139" 138 "138" 137 "137" 136 "136" 135 "135" 134 "134" 133 "133" 132 "132" 131 "131" 130 "130" 129 "129" 128 "128" 127 "127" 126 "126" 125 "125" 124 "124" 123 "123" 122 "122" 121 "121" 120 "120" 119 "119" 118 "118" 117 "117" 116 "116" 115 "115" 114 "114" 113 "113" 112 "112" 111 "111" 110 "110" 109 "109" 108 "108" 107 "107" 106 "106" 105 "105" 104 "104" 103 "103" 102 "102" 101 "101" 100 "100" 99 "99" 98 "98" 97 "97" 96 "96" 95 "95" 94 "94" 93 "93" 92 "92" 91 "91" 90 "90" 89 "89" 88 "88" 87 "87" 86 "86" 85 "85" 84 "84" 83 "83" 82 "82" 81 "81" 80 "80" 79 "79" 78 "78" 77 "77" 76 "76" 75 "75" 74 "74" 73 "73" 72 "72" 71 "71" 70 "70" 69 "69" 68 "68" 67 "67" 66 "66" 65 "65" 64 "64" 63 "63" 62 "62" 61 "61" 60 "60" 59 "59" 58 "58" 57 "57" 56 "56" 55 "55" 54 "54" 53 "53" 52 "52" 51 "51" 50 "50" 49 "49" 48 "48" 47 "47" 46 "46" 45 "45" 44 "44" 43 "43" 42 "42" 41 "41" 40 "40" 39 "39" 38 "38" 37 "37" 36 "36" 35 "35" 34 "34" 33 "33" 32 "32" 31 "31" 30 "30" 29 "29" 28 "28" 27 "27" 26 "26" 25 "25" 24 "24" 23 "23" 22 "22" 21 "21" 20 "20" 19 "19" 18 "18" 17 "17" 16 "16" 15 "15" 14 "14" 13 "13" 12 "12" 11 "11" 10 "10" 9 "9" 8 "8" 7 "7" 6 "6" 5 "5" 4 "4" 3 "3" 2 "2" 1 "1" 0 "Unknown" ;
VAL_ 656 DAS_ADBLeftLED6_Req 1 "On" 0 "Off" ;
VAL_ 656 DAS_LeftObj_6_Y_1_Val 321 "Error" 320 "320" 319 "319" 318 "318" 317 "317" 316 "316" 315 "315" 314 "314" 313 "313" 312 "312" 311 "311" 310 "310" 309 "309" 308 "308" 307 "307" 306 "306" 305 "305" 304 "304" 303 "303" 302 "302" 301 "301" 300 "300" 299 "299" 298 "298" 297 "297" 296 "296" 295 "295" 294 "294" 293 "293" 292 "292" 291 "291" 290 "290" 289 "289" 288 "288" 287 "287" 286 "286" 285 "285" 284 "284" 283 "283" 282 "282" 281 "281" 280 "280" 279 "279" 278 "278" 277 "277" 276 "276" 275 "275" 274 "274" 273 "273" 272 "272" 271 "271" 270 "270" 269 "269" 268 "268" 267 "267" 266 "266" 265 "265" 264 "264" 263 "263" 262 "262" 261 "261" 260 "260" 259 "259" 258 "258" 257 "257" 256 "256" 255 "255" 254 "254" 253 "253" 252 "252" 251 "251" 250 "250" 249 "249" 248 "248" 247 "247" 246 "246" 245 "245" 244 "244" 243 "243" 242 "242" 241 "241" 240 "240" 239 "239" 238 "238" 237 "237" 236 "236" 235 "235" 234 "234" 233 "233" 232 "232" 231 "231" 230 "230" 229 "229" 228 "228" 227 "227" 226 "226" 225 "225" 224 "224" 223 "223" 222 "222" 221 "221" 220 "220" 219 "219" 218 "218" 217 "217" 216 "216" 215 "215" 214 "214" 213 "213" 212 "212" 211 "211" 210 "210" 209 "209" 208 "208" 207 "207" 206 "206" 205 "205" 204 "204" 203 "203" 202 "202" 201 "201" 200 "200" 199 "199" 198 "198" 197 "197" 196 "196" 195 "195" 194 "194" 193 "193" 192 "192" 191 "191" 190 "190" 189 "189" 188 "188" 187 "187" 186 "186" 185 "185" 184 "184" 183 "183" 182 "182" 181 "181" 180 "180" 179 "179" 178 "178" 177 "177" 176 "176" 175 "175" 174 "174" 173 "173" 172 "172" 171 "171" 170 "170" 169 "169" 168 "168" 167 "167" 166 "166" 165 "165" 164 "164" 163 "163" 162 "162" 161 "161" 160 "160" 159 "159" 158 "158" 157 "157" 156 "156" 155 "155" 154 "154" 153 "153" 152 "152" 151 "151" 150 "150" 149 "149" 148 "148" 147 "147" 146 "146" 145 "145" 144 "144" 143 "143" 142 "142" 141 "141" 140 "140" 139 "139" 138 "138" 137 "137" 136 "136" 135 "135" 134 "134" 133 "133" 132 "132" 131 "131" 130 "130" 129 "129" 128 "128" 127 "127" 126 "126" 125 "125" 124 "124" 123 "123" 122 "122" 121 "121" 120 "120" 119 "119" 118 "118" 117 "117" 116 "116" 115 "115" 114 "114" 113 "113" 112 "112" 111 "111" 110 "110" 109 "109" 108 "108" 107 "107" 106 "106" 105 "105" 104 "104" 103 "103" 102 "102" 101 "101" 100 "100" 99 "99" 98 "98" 97 "97" 96 "96" 95 "95" 94 "94" 93 "93" 92 "92" 91 "91" 90 "90" 89 "89" 88 "88" 87 "87" 86 "86" 85 "85" 84 "84" 83 "83" 82 "82" 81 "81" 80 "80" 79 "79" 78 "78" 77 "77" 76 "76" 75 "75" 74 "74" 73 "73" 72 "72" 71 "71" 70 "70" 69 "69" 68 "68" 67 "67" 66 "66" 65 "65" 64 "64" 63 "63" 62 "62" 61 "61" 60 "60" 59 "59" 58 "58" 57 "57" 56 "56" 55 "55" 54 "54" 53 "53" 52 "52" 51 "51" 50 "50" 49 "49" 48 "48" 47 "47" 46 "46" 45 "45" 44 "44" 43 "43" 42 "42" 41 "41" 40 "40" 39 "39" 38 "38" 37 "37" 36 "36" 35 "35" 34 "34" 33 "33" 32 "32" 31 "31" 30 "30" 29 "29" 28 "28" 27 "27" 26 "26" 25 "25" 24 "24" 23 "23" 22 "22" 21 "21" 20 "20" 19 "19" 18 "18" 17 "17" 16 "16" 15 "15" 14 "14" 13 "13" 12 "12" 11 "11" 10 "10" 9 "9" 8 "8" 7 "7" 6 "6" 5 "5" 4 "4" 3 "3" 2 "2" 1 "1" 0 "Unknown" ;
VAL_ 656 DAS_LeftObj_5_Z_2_Val 81 "Error" 80 "80" 79 "79" 78 "78" 77 "77" 76 "76" 75 "75" 74 "74" 73 "73" 72 "72" 71 "71" 70 "70" 69 "69" 68 "68" 67 "67" 66 "66" 65 "65" 64 "64" 63 "63" 62 "62" 61 "61" 60 "60" 59 "59" 58 "58" 57 "57" 56 "56" 55 "55" 54 "54" 53 "53" 52 "52" 51 "51" 50 "50" 49 "49" 48 "48" 47 "47" 46 "46" 45 "45" 44 "44" 43 "43" 42 "42" 41 "41" 40 "40" 39 "39" 38 "38" 37 "37" 36 "36" 35 "35" 34 "34" 33 "33" 32 "32" 31 "31" 30 "30" 29 "29" 28 "28" 27 "27" 26 "26" 25 "25" 24 "24" 23 "23" 22 "22" 21 "21" 20 "20" 19 "19" 18 "18" 17 "17" 16 "16" 15 "15" 14 "14" 13 "13" 12 "12" 11 "11" 10 "10" 9 "9" 8 "8" 7 "7" 6 "6" 5 "5" 4 "4" 3 "3" 2 "2" 1 "1" 0 "Unknown" ;
VAL_ 656 DAS_LeftObj_9_Z_2_Val 81 "Error" 80 "80" 79 "79" 78 "78" 77 "77" 76 "76" 75 "75" 74 "74" 73 "73" 72 "72" 71 "71" 70 "70" 69 "69" 68 "68" 67 "67" 66 "66" 65 "65" 64 "64" 63 "63" 62 "62" 61 "61" 60 "60" 59 "59" 58 "58" 57 "57" 56 "56" 55 "55" 54 "54" 53 "53" 52 "52" 51 "51" 50 "50" 49 "49" 48 "48" 47 "47" 46 "46" 45 "45" 44 "44" 43 "43" 42 "42" 41 "41" 40 "40" 39 "39" 38 "38" 37 "37" 36 "36" 35 "35" 34 "34" 33 "33" 32 "32" 31 "31" 30 "30" 29 "29" 28 "28" 27 "27" 26 "26" 25 "25" 24 "24" 23 "23" 22 "22" 21 "21" 20 "20" 19 "19" 18 "18" 17 "17" 16 "16" 15 "15" 14 "14" 13 "13" 12 "12" 11 "11" 10 "10" 9 "9" 8 "8" 7 "7" 6 "6" 5 "5" 4 "4" 3 "3" 2 "2" 1 "1" 0 "Unknown" ;
VAL_ 656 DAS_LeftObj_5_Y_1_Val 321 "Error" 320 "320" 319 "319" 318 "318" 317 "317" 316 "316" 315 "315" 314 "314" 313 "313" 312 "312" 311 "311" 310 "310" 309 "309" 308 "308" 307 "307" 306 "306" 305 "305" 304 "304" 303 "303" 302 "302" 301 "301" 300 "300" 299 "299" 298 "298" 297 "297" 296 "296" 295 "295" 294 "294" 293 "293" 292 "292" 291 "291" 290 "290" 289 "289" 288 "288" 287 "287" 286 "286" 285 "285" 284 "284" 283 "283" 282 "282" 281 "281" 280 "280" 279 "279" 278 "278" 277 "277" 276 "276" 275 "275" 274 "274" 273 "273" 272 "272" 271 "271" 270 "270" 269 "269" 268 "268" 267 "267" 266 "266" 265 "265" 264 "264" 263 "263" 262 "262" 261 "261" 260 "260" 259 "259" 258 "258" 257 "257" 256 "256" 255 "255" 254 "254" 253 "253" 252 "252" 251 "251" 250 "250" 249 "249" 248 "248" 247 "247" 246 "246" 245 "245" 244 "244" 243 "243" 242 "242" 241 "241" 240 "240" 239 "239" 238 "238" 237 "237" 236 "236" 235 "235" 234 "234" 233 "233" 232 "232" 231 "231" 230 "230" 229 "229" 228 "228" 227 "227" 226 "226" 225 "225" 224 "224" 223 "223" 222 "222" 221 "221" 220 "220" 219 "219" 218 "218" 217 "217" 216 "216" 215 "215" 214 "214" 213 "213" 212 "212" 211 "211" 210 "210" 209 "209" 208 "208" 207 "207" 206 "206" 205 "205" 204 "204" 203 "203" 202 "202" 201 "201" 200 "200" 199 "199" 198 "198" 197 "197" 196 "196" 195 "195" 194 "194" 193 "193" 192 "192" 191 "191" 190 "190" 189 "189" 188 "188" 187 "187" 186 "186" 185 "185" 184 "184" 183 "183" 182 "182" 181 "181" 180 "180" 179 "179" 178 "178" 177 "177" 176 "176" 175 "175" 174 "174" 173 "173" 172 "172" 171 "171" 170 "170" 169 "169" 168 "168" 167 "167" 166 "166" 165 "165" 164 "164" 163 "163" 162 "162" 161 "161" 160 "160" 159 "159" 158 "158" 157 "157" 156 "156" 155 "155" 154 "154" 153 "153" 152 "152" 151 "151" 150 "150" 149 "149" 148 "148" 147 "147" 146 "146" 145 "145" 144 "144" 143 "143" 142 "142" 141 "141" 140 "140" 139 "139" 138 "138" 137 "137" 136 "136" 135 "135" 134 "134" 133 "133" 132 "132" 131 "131" 130 "130" 129 "129" 128 "128" 127 "127" 126 "126" 125 "125" 124 "124" 123 "123" 122 "122" 121 "121" 120 "120" 119 "119" 118 "118" 117 "117" 116 "116" 115 "115" 114 "114" 113 "113" 112 "112" 111 "111" 110 "110" 109 "109" 108 "108" 107 "107" 106 "106" 105 "105" 104 "104" 103 "103" 102 "102" 101 "101" 100 "100" 99 "99" 98 "98" 97 "97" 96 "96" 95 "95" 94 "94" 93 "93" 92 "92" 91 "91" 90 "90" 89 "89" 88 "88" 87 "87" 86 "86" 85 "85" 84 "84" 83 "83" 82 "82" 81 "81" 80 "80" 79 "79" 78 "78" 77 "77" 76 "76" 75 "75" 74 "74" 73 "73" 72 "72" 71 "71" 70 "70" 69 "69" 68 "68" 67 "67" 66 "66" 65 "65" 64 "64" 63 "63" 62 "62" 61 "61" 60 "60" 59 "59" 58 "58" 57 "57" 56 "56" 55 "55" 54 "54" 53 "53" 52 "52" 51 "51" 50 "50" 49 "49" 48 "48" 47 "47" 46 "46" 45 "45" 44 "44" 43 "43" 42 "42" 41 "41" 40 "40" 39 "39" 38 "38" 37 "37" 36 "36" 35 "35" 34 "34" 33 "33" 32 "32" 31 "31" 30 "30" 29 "29" 28 "28" 27 "27" 26 "26" 25 "25" 24 "24" 23 "23" 22 "22" 21 "21" 20 "20" 19 "19" 18 "18" 17 "17" 16 "16" 15 "15" 14 "14" 13 "13" 12 "12" 11 "11" 10 "10" 9 "9" 8 "8" 7 "7" 6 "6" 5 "5" 4 "4" 3 "3" 2 "2" 1 "1" 0 "Unknown" ;
VAL_ 656 DAS_LeftObj_1_Y_2_Val 321 "Error" 320 "320" 319 "319" 318 "318" 317 "317" 316 "316" 315 "315" 314 "314" 313 "313" 312 "312" 311 "311" 310 "310" 309 "309" 308 "308" 307 "307" 306 "306" 305 "305" 304 "304" 303 "303" 302 "302" 301 "301" 300 "300" 299 "299" 298 "298" 297 "297" 296 "296" 295 "295" 294 "294" 293 "293" 292 "292" 291 "291" 290 "290" 289 "289" 288 "288" 287 "287" 286 "286" 285 "285" 284 "284" 283 "283" 282 "282" 281 "281" 280 "280" 279 "279" 278 "278" 277 "277" 276 "276" 275 "275" 274 "274" 273 "273" 272 "272" 271 "271" 270 "270" 269 "269" 268 "268" 267 "267" 266 "266" 265 "265" 264 "264" 263 "263" 262 "262" 261 "261" 260 "260" 259 "259" 258 "258" 257 "257" 256 "256" 255 "255" 254 "254" 253 "253" 252 "252" 251 "251" 250 "250" 249 "249" 248 "248" 247 "247" 246 "246" 245 "245" 244 "244" 243 "243" 242 "242" 241 "241" 240 "240" 239 "239" 238 "238" 237 "237" 236 "236" 235 "235" 234 "234" 233 "233" 232 "232" 231 "231" 230 "230" 229 "229" 228 "228" 227 "227" 226 "226" 225 "225" 224 "224" 223 "223" 222 "222" 221 "221" 220 "220" 219 "219" 218 "218" 217 "217" 216 "216" 215 "215" 214 "214" 213 "213" 212 "212" 211 "211" 210 "210" 209 "209" 208 "208" 207 "207" 206 "206" 205 "205" 204 "204" 203 "203" 202 "202" 201 "201" 200 "200" 199 "199" 198 "198" 197 "197" 196 "196" 195 "195" 194 "194" 193 "193" 192 "192" 191 "191" 190 "190" 189 "189" 188 "188" 187 "187" 186 "186" 185 "185" 184 "184" 183 "183" 182 "182" 181 "181" 180 "180" 179 "179" 178 "178" 177 "177" 176 "176" 175 "175" 174 "174" 173 "173" 172 "172" 171 "171" 170 "170" 169 "169" 168 "168" 167 "167" 166 "166" 165 "165" 164 "164" 163 "163" 162 "162" 161 "161" 160 "160" 159 "159" 158 "158" 157 "157" 156 "156" 155 "155" 154 "154" 153 "153" 152 "152" 151 "151" 150 "150" 149 "149" 148 "148" 147 "147" 146 "146" 145 "145" 144 "144" 143 "143" 142 "142" 141 "141" 140 "140" 139 "139" 138 "138" 137 "137" 136 "136" 135 "135" 134 "134" 133 "133" 132 "132" 131 "131" 130 "130" 129 "129" 128 "128" 127 "127" 126 "126" 125 "125" 124 "124" 123 "123" 122 "122" 121 "121" 120 "120" 119 "119" 118 "118" 117 "117" 116 "116" 115 "115" 114 "114" 113 "113" 112 "112" 111 "111" 110 "110" 109 "109" 108 "108" 107 "107" 106 "106" 105 "105" 104 "104" 103 "103" 102 "102" 101 "101" 100 "100" 99 "99" 98 "98" 97 "97" 96 "96" 95 "95" 94 "94" 93 "93" 92 "92" 91 "91" 90 "90" 89 "89" 88 "88" 87 "87" 86 "86" 85 "85" 84 "84" 83 "83" 82 "82" 81 "81" 80 "80" 79 "79" 78 "78" 77 "77" 76 "76" 75 "75" 74 "74" 73 "73" 72 "72" 71 "71" 70 "70" 69 "69" 68 "68" 67 "67" 66 "66" 65 "65" 64 "64" 63 "63" 62 "62" 61 "61" 60 "60" 59 "59" 58 "58" 57 "57" 56 "56" 55 "55" 54 "54" 53 "53" 52 "52" 51 "51" 50 "50" 49 "49" 48 "48" 47 "47" 46 "46" 45 "45" 44 "44" 43 "43" 42 "42" 41 "41" 40 "40" 39 "39" 38 "38" 37 "37" 36 "36" 35 "35" 34 "34" 33 "33" 32 "32" 31 "31" 30 "30" 29 "29" 28 "28" 27 "27" 26 "26" 25 "25" 24 "24" 23 "23" 22 "22" 21 "21" 20 "20" 19 "19" 18 "18" 17 "17" 16 "16" 15 "15" 14 "14" 13 "13" 12 "12" 11 "11" 10 "10" 9 "9" 8 "8" 7 "7" 6 "6" 5 "5" 4 "4" 3 "3" 2 "2" 1 "1" 0 "Unknown" ;
VAL_ 656 DAS_LeftObj_2_Z_1_Val 81 "Error" 80 "80" 79 "79" 78 "78" 77 "77" 76 "76" 75 "75" 74 "74" 73 "73" 72 "72" 71 "71" 70 "70" 69 "69" 68 "68" 67 "67" 66 "66" 65 "65" 64 "64" 63 "63" 62 "62" 61 "61" 60 "60" 59 "59" 58 "58" 57 "57" 56 "56" 55 "55" 54 "54" 53 "53" 52 "52" 51 "51" 50 "50" 49 "49" 48 "48" 47 "47" 46 "46" 45 "45" 44 "44" 43 "43" 42 "42" 41 "41" 40 "40" 39 "39" 38 "38" 37 "37" 36 "36" 35 "35" 34 "34" 33 "33" 32 "32" 31 "31" 30 "30" 29 "29" 28 "28" 27 "27" 26 "26" 25 "25" 24 "24" 23 "23" 22 "22" 21 "21" 20 "20" 19 "19" 18 "18" 17 "17" 16 "16" 15 "15" 14 "14" 13 "13" 12 "12" 11 "11" 10 "10" 9 "9" 8 "8" 7 "7" 6 "6" 5 "5" 4 "4" 3 "3" 2 "2" 1 "1" 0 "Unknown" ;
VAL_ 656 DAS_LeftObj_1_Z_2_Val 81 "Error" 80 "80" 79 "79" 78 "78" 77 "77" 76 "76" 75 "75" 74 "74" 73 "73" 72 "72" 71 "71" 70 "70" 69 "69" 68 "68" 67 "67" 66 "66" 65 "65" 64 "64" 63 "63" 62 "62" 61 "61" 60 "60" 59 "59" 58 "58" 57 "57" 56 "56" 55 "55" 54 "54" 53 "53" 52 "52" 51 "51" 50 "50" 49 "49" 48 "48" 47 "47" 46 "46" 45 "45" 44 "44" 43 "43" 42 "42" 41 "41" 40 "40" 39 "39" 38 "38" 37 "37" 36 "36" 35 "35" 34 "34" 33 "33" 32 "32" 31 "31" 30 "30" 29 "29" 28 "28" 27 "27" 26 "26" 25 "25" 24 "24" 23 "23" 22 "22" 21 "21" 20 "20" 19 "19" 18 "18" 17 "17" 16 "16" 15 "15" 14 "14" 13 "13" 12 "12" 11 "11" 10 "10" 9 "9" 8 "8" 7 "7" 6 "6" 5 "5" 4 "4" 3 "3" 2 "2" 1 "1" 0 "Unknown" ;
VAL_ 656 DAS_ADBLeftLED13_Req 1 "On" 0 "Off" ;
VAL_ 656 DAS_LeftObj_9_Y_2_Val 321 "Error" 320 "320" 319 "319" 318 "318" 317 "317" 316 "316" 315 "315" 314 "314" 313 "313" 312 "312" 311 "311" 310 "310" 309 "309" 308 "308" 307 "307" 306 "306" 305 "305" 304 "304" 303 "303" 302 "302" 301 "301" 300 "300" 299 "299" 298 "298" 297 "297" 296 "296" 295 "295" 294 "294" 293 "293" 292 "292" 291 "291" 290 "290" 289 "289" 288 "288" 287 "287" 286 "286" 285 "285" 284 "284" 283 "283" 282 "282" 281 "281" 280 "280" 279 "279" 278 "278" 277 "277" 276 "276" 275 "275" 274 "274" 273 "273" 272 "272" 271 "271" 270 "270" 269 "269" 268 "268" 267 "267" 266 "266" 265 "265" 264 "264" 263 "263" 262 "262" 261 "261" 260 "260" 259 "259" 258 "258" 257 "257" 256 "256" 255 "255" 254 "254" 253 "253" 252 "252" 251 "251" 250 "250" 249 "249" 248 "248" 247 "247" 246 "246" 245 "245" 244 "244" 243 "243" 242 "242" 241 "241" 240 "240" 239 "239" 238 "238" 237 "237" 236 "236" 235 "235" 234 "234" 233 "233" 232 "232" 231 "231" 230 "230" 229 "229" 228 "228" 227 "227" 226 "226" 225 "225" 224 "224" 223 "223" 222 "222" 221 "221" 220 "220" 219 "219" 218 "218" 217 "217" 216 "216" 215 "215" 214 "214" 213 "213" 212 "212" 211 "211" 210 "210" 209 "209" 208 "208" 207 "207" 206 "206" 205 "205" 204 "204" 203 "203" 202 "202" 201 "201" 200 "200" 199 "199" 198 "198" 197 "197" 196 "196" 195 "195" 194 "194" 193 "193" 192 "192" 191 "191" 190 "190" 189 "189" 188 "188" 187 "187" 186 "186" 185 "185" 184 "184" 183 "183" 182 "182" 181 "181" 180 "180" 179 "179" 178 "178" 177 "177" 176 "176" 175 "175" 174 "174" 173 "173" 172 "172" 171 "171" 170 "170" 169 "169" 168 "168" 167 "167" 166 "166" 165 "165" 164 "164" 163 "163" 162 "162" 161 "161" 160 "160" 159 "159" 158 "158" 157 "157" 156 "156" 155 "155" 154 "154" 153 "153" 152 "152" 151 "151" 150 "150" 149 "149" 148 "148" 147 "147" 146 "146" 145 "145" 144 "144" 143 "143" 142 "142" 141 "141" 140 "140" 139 "139" 138 "138" 137 "137" 136 "136" 135 "135" 134 "134" 133 "133" 132 "132" 131 "131" 130 "130" 129 "129" 128 "128" 127 "127" 126 "126" 125 "125" 124 "124" 123 "123" 122 "122" 121 "121" 120 "120" 119 "119" 118 "118" 117 "117" 116 "116" 115 "115" 114 "114" 113 "113" 112 "112" 111 "111" 110 "110" 109 "109" 108 "108" 107 "107" 106 "106" 105 "105" 104 "104" 103 "103" 102 "102" 101 "101" 100 "100" 99 "99" 98 "98" 97 "97" 96 "96" 95 "95" 94 "94" 93 "93" 92 "92" 91 "91" 90 "90" 89 "89" 88 "88" 87 "87" 86 "86" 85 "85" 84 "84" 83 "83" 82 "82" 81 "81" 80 "80" 79 "79" 78 "78" 77 "77" 76 "76" 75 "75" 74 "74" 73 "73" 72 "72" 71 "71" 70 "70" 69 "69" 68 "68" 67 "67" 66 "66" 65 "65" 64 "64" 63 "63" 62 "62" 61 "61" 60 "60" 59 "59" 58 "58" 57 "57" 56 "56" 55 "55" 54 "54" 53 "53" 52 "52" 51 "51" 50 "50" 49 "49" 48 "48" 47 "47" 46 "46" 45 "45" 44 "44" 43 "43" 42 "42" 41 "41" 40 "40" 39 "39" 38 "38" 37 "37" 36 "36" 35 "35" 34 "34" 33 "33" 32 "32" 31 "31" 30 "30" 29 "29" 28 "28" 27 "27" 26 "26" 25 "25" 24 "24" 23 "23" 22 "22" 21 "21" 20 "20" 19 "19" 18 "18" 17 "17" 16 "16" 15 "15" 14 "14" 13 "13" 12 "12" 11 "11" 10 "10" 9 "9" 8 "8" 7 "7" 6 "6" 5 "5" 4 "4" 3 "3" 2 "2" 1 "1" 0 "Unknown" ;
VAL_ 656 DAS_LeftObj_6_Z_2_Val 81 "Error" 80 "80" 79 "79" 78 "78" 77 "77" 76 "76" 75 "75" 74 "74" 73 "73" 72 "72" 71 "71" 70 "70" 69 "69" 68 "68" 67 "67" 66 "66" 65 "65" 64 "64" 63 "63" 62 "62" 61 "61" 60 "60" 59 "59" 58 "58" 57 "57" 56 "56" 55 "55" 54 "54" 53 "53" 52 "52" 51 "51" 50 "50" 49 "49" 48 "48" 47 "47" 46 "46" 45 "45" 44 "44" 43 "43" 42 "42" 41 "41" 40 "40" 39 "39" 38 "38" 37 "37" 36 "36" 35 "35" 34 "34" 33 "33" 32 "32" 31 "31" 30 "30" 29 "29" 28 "28" 27 "27" 26 "26" 25 "25" 24 "24" 23 "23" 22 "22" 21 "21" 20 "20" 19 "19" 18 "18" 17 "17" 16 "16" 15 "15" 14 "14" 13 "13" 12 "12" 11 "11" 10 "10" 9 "9" 8 "8" 7 "7" 6 "6" 5 "5" 4 "4" 3 "3" 2 "2" 1 "1" 0 "Unknown" ;
VAL_ 656 DAS_LeftObj_7_Z_2_Val 81 "Error" 80 "80" 79 "79" 78 "78" 77 "77" 76 "76" 75 "75" 74 "74" 73 "73" 72 "72" 71 "71" 70 "70" 69 "69" 68 "68" 67 "67" 66 "66" 65 "65" 64 "64" 63 "63" 62 "62" 61 "61" 60 "60" 59 "59" 58 "58" 57 "57" 56 "56" 55 "55" 54 "54" 53 "53" 52 "52" 51 "51" 50 "50" 49 "49" 48 "48" 47 "47" 46 "46" 45 "45" 44 "44" 43 "43" 42 "42" 41 "41" 40 "40" 39 "39" 38 "38" 37 "37" 36 "36" 35 "35" 34 "34" 33 "33" 32 "32" 31 "31" 30 "30" 29 "29" 28 "28" 27 "27" 26 "26" 25 "25" 24 "24" 23 "23" 22 "22" 21 "21" 20 "20" 19 "19" 18 "18" 17 "17" 16 "16" 15 "15" 14 "14" 13 "13" 12 "12" 11 "11" 10 "10" 9 "9" 8 "8" 7 "7" 6 "6" 5 "5" 4 "4" 3 "3" 2 "2" 1 "1" 0 "Unknown" ;
VAL_ 656 DAS_LeftObj_6_Z_1_Val 81 "Error" 80 "80" 79 "79" 78 "78" 77 "77" 76 "76" 75 "75" 74 "74" 73 "73" 72 "72" 71 "71" 70 "70" 69 "69" 68 "68" 67 "67" 66 "66" 65 "65" 64 "64" 63 "63" 62 "62" 61 "61" 60 "60" 59 "59" 58 "58" 57 "57" 56 "56" 55 "55" 54 "54" 53 "53" 52 "52" 51 "51" 50 "50" 49 "49" 48 "48" 47 "47" 46 "46" 45 "45" 44 "44" 43 "43" 42 "42" 41 "41" 40 "40" 39 "39" 38 "38" 37 "37" 36 "36" 35 "35" 34 "34" 33 "33" 32 "32" 31 "31" 30 "30" 29 "29" 28 "28" 27 "27" 26 "26" 25 "25" 24 "24" 23 "23" 22 "22" 21 "21" 20 "20" 19 "19" 18 "18" 17 "17" 16 "16" 15 "15" 14 "14" 13 "13" 12 "12" 11 "11" 10 "10" 9 "9" 8 "8" 7 "7" 6 "6" 5 "5" 4 "4" 3 "3" 2 "2" 1 "1" 0 "Unknown" ;
VAL_ 656 DAS_ADBLeftLED14_Req 1 "On" 0 "Off" ;
VAL_ 656 DAS_LeftObj_5_Y_2_Val 321 "Error" 320 "320" 319 "319" 318 "318" 317 "317" 316 "316" 315 "315" 314 "314" 313 "313" 312 "312" 311 "311" 310 "310" 309 "309" 308 "308" 307 "307" 306 "306" 305 "305" 304 "304" 303 "303" 302 "302" 301 "301" 300 "300" 299 "299" 298 "298" 297 "297" 296 "296" 295 "295" 294 "294" 293 "293" 292 "292" 291 "291" 290 "290" 289 "289" 288 "288" 287 "287" 286 "286" 285 "285" 284 "284" 283 "283" 282 "282" 281 "281" 280 "280" 279 "279" 278 "278" 277 "277" 276 "276" 275 "275" 274 "274" 273 "273" 272 "272" 271 "271" 270 "270" 269 "269" 268 "268" 267 "267" 266 "266" 265 "265" 264 "264" 263 "263" 262 "262" 261 "261" 260 "260" 259 "259" 258 "258" 257 "257" 256 "256" 255 "255" 254 "254" 253 "253" 252 "252" 251 "251" 250 "250" 249 "249" 248 "248" 247 "247" 246 "246" 245 "245" 244 "244" 243 "243" 242 "242" 241 "241" 240 "240" 239 "239" 238 "238" 237 "237" 236 "236" 235 "235" 234 "234" 233 "233" 232 "232" 231 "231" 230 "230" 229 "229" 228 "228" 227 "227" 226 "226" 225 "225" 224 "224" 223 "223" 222 "222" 221 "221" 220 "220" 219 "219" 218 "218" 217 "217" 216 "216" 215 "215" 214 "214" 213 "213" 212 "212" 211 "211" 210 "210" 209 "209" 208 "208" 207 "207" 206 "206" 205 "205" 204 "204" 203 "203" 202 "202" 201 "201" 200 "200" 199 "199" 198 "198" 197 "197" 196 "196" 195 "195" 194 "194" 193 "193" 192 "192" 191 "191" 190 "190" 189 "189" 188 "188" 187 "187" 186 "186" 185 "185" 184 "184" 183 "183" 182 "182" 181 "181" 180 "180" 179 "179" 178 "178" 177 "177" 176 "176" 175 "175" 174 "174" 173 "173" 172 "172" 171 "171" 170 "170" 169 "169" 168 "168" 167 "167" 166 "166" 165 "165" 164 "164" 163 "163" 162 "162" 161 "161" 160 "160" 159 "159" 158 "158" 157 "157" 156 "156" 155 "155" 154 "154" 153 "153" 152 "152" 151 "151" 150 "150" 149 "149" 148 "148" 147 "147" 146 "146" 145 "145" 144 "144" 143 "143" 142 "142" 141 "141" 140 "140" 139 "139" 138 "138" 137 "137" 136 "136" 135 "135" 134 "134" 133 "133" 132 "132" 131 "131" 130 "130" 129 "129" 128 "128" 127 "127" 126 "126" 125 "125" 124 "124" 123 "123" 122 "122" 121 "121" 120 "120" 119 "119" 118 "118" 117 "117" 116 "116" 115 "115" 114 "114" 113 "113" 112 "112" 111 "111" 110 "110" 109 "109" 108 "108" 107 "107" 106 "106" 105 "105" 104 "104" 103 "103" 102 "102" 101 "101" 100 "100" 99 "99" 98 "98" 97 "97" 96 "96" 95 "95" 94 "94" 93 "93" 92 "92" 91 "91" 90 "90" 89 "89" 88 "88" 87 "87" 86 "86" 85 "85" 84 "84" 83 "83" 82 "82" 81 "81" 80 "80" 79 "79" 78 "78" 77 "77" 76 "76" 75 "75" 74 "74" 73 "73" 72 "72" 71 "71" 70 "70" 69 "69" 68 "68" 67 "67" 66 "66" 65 "65" 64 "64" 63 "63" 62 "62" 61 "61" 60 "60" 59 "59" 58 "58" 57 "57" 56 "56" 55 "55" 54 "54" 53 "53" 52 "52" 51 "51" 50 "50" 49 "49" 48 "48" 47 "47" 46 "46" 45 "45" 44 "44" 43 "43" 42 "42" 41 "41" 40 "40" 39 "39" 38 "38" 37 "37" 36 "36" 35 "35" 34 "34" 33 "33" 32 "32" 31 "31" 30 "30" 29 "29" 28 "28" 27 "27" 26 "26" 25 "25" 24 "24" 23 "23" 22 "22" 21 "21" 20 "20" 19 "19" 18 "18" 17 "17" 16 "16" 15 "15" 14 "14" 13 "13" 12 "12" 11 "11" 10 "10" 9 "9" 8 "8" 7 "7" 6 "6" 5 "5" 4 "4" 3 "3" 2 "2" 1 "1" 0 "Unknown" ;
VAL_ 656 DAS_LeftObj_7_Z_1_Val 81 "Error" 80 "80" 79 "79" 78 "78" 77 "77" 76 "76" 75 "75" 74 "74" 73 "73" 72 "72" 71 "71" 70 "70" 69 "69" 68 "68" 67 "67" 66 "66" 65 "65" 64 "64" 63 "63" 62 "62" 61 "61" 60 "60" 59 "59" 58 "58" 57 "57" 56 "56" 55 "55" 54 "54" 53 "53" 52 "52" 51 "51" 50 "50" 49 "49" 48 "48" 47 "47" 46 "46" 45 "45" 44 "44" 43 "43" 42 "42" 41 "41" 40 "40" 39 "39" 38 "38" 37 "37" 36 "36" 35 "35" 34 "34" 33 "33" 32 "32" 31 "31" 30 "30" 29 "29" 28 "28" 27 "27" 26 "26" 25 "25" 24 "24" 23 "23" 22 "22" 21 "21" 20 "20" 19 "19" 18 "18" 17 "17" 16 "16" 15 "15" 14 "14" 13 "13" 12 "12" 11 "11" 10 "10" 9 "9" 8 "8" 7 "7" 6 "6" 5 "5" 4 "4" 3 "3" 2 "2" 1 "1" 0 "Unknown" ;
VAL_ 656 DAS_ADBLeftLED2_Req 1 "On" 0 "Off" ;
VAL_ 656 DAS_LeftObj_6_Y_2_Val 321 "Error" 320 "320" 319 "319" 318 "318" 317 "317" 316 "316" 315 "315" 314 "314" 313 "313" 312 "312" 311 "311" 310 "310" 309 "309" 308 "308" 307 "307" 306 "306" 305 "305" 304 "304" 303 "303" 302 "302" 301 "301" 300 "300" 299 "299" 298 "298" 297 "297" 296 "296" 295 "295" 294 "294" 293 "293" 292 "292" 291 "291" 290 "290" 289 "289" 288 "288" 287 "287" 286 "286" 285 "285" 284 "284" 283 "283" 282 "282" 281 "281" 280 "280" 279 "279" 278 "278" 277 "277" 276 "276" 275 "275" 274 "274" 273 "273" 272 "272" 271 "271" 270 "270" 269 "269" 268 "268" 267 "267" 266 "266" 265 "265" 264 "264" 263 "263" 262 "262" 261 "261" 260 "260" 259 "259" 258 "258" 257 "257" 256 "256" 255 "255" 254 "254" 253 "253" 252 "252" 251 "251" 250 "250" 249 "249" 248 "248" 247 "247" 246 "246" 245 "245" 244 "244" 243 "243" 242 "242" 241 "241" 240 "240" 239 "239" 238 "238" 237 "237" 236 "236" 235 "235" 234 "234" 233 "233" 232 "232" 231 "231" 230 "230" 229 "229" 228 "228" 227 "227" 226 "226" 225 "225" 224 "224" 223 "223" 222 "222" 221 "221" 220 "220" 219 "219" 218 "218" 217 "217" 216 "216" 215 "215" 214 "214" 213 "213" 212 "212" 211 "211" 210 "210" 209 "209" 208 "208" 207 "207" 206 "206" 205 "205" 204 "204" 203 "203" 202 "202" 201 "201" 200 "200" 199 "199" 198 "198" 197 "197" 196 "196" 195 "195" 194 "194" 193 "193" 192 "192" 191 "191" 190 "190" 189 "189" 188 "188" 187 "187" 186 "186" 185 "185" 184 "184" 183 "183" 182 "182" 181 "181" 180 "180" 179 "179" 178 "178" 177 "177" 176 "176" 175 "175" 174 "174" 173 "173" 172 "172" 171 "171" 170 "170" 169 "169" 168 "168" 167 "167" 166 "166" 165 "165" 164 "164" 163 "163" 162 "162" 161 "161" 160 "160" 159 "159" 158 "158" 157 "157" 156 "156" 155 "155" 154 "154" 153 "153" 152 "152" 151 "151" 150 "150" 149 "149" 148 "148" 147 "147" 146 "146" 145 "145" 144 "144" 143 "143" 142 "142" 141 "141" 140 "140" 139 "139" 138 "138" 137 "137" 136 "136" 135 "135" 134 "134" 133 "133" 132 "132" 131 "131" 130 "130" 129 "129" 128 "128" 127 "127" 126 "126" 125 "125" 124 "124" 123 "123" 122 "122" 121 "121" 120 "120" 119 "119" 118 "118" 117 "117" 116 "116" 115 "115" 114 "114" 113 "113" 112 "112" 111 "111" 110 "110" 109 "109" 108 "108" 107 "107" 106 "106" 105 "105" 104 "104" 103 "103" 102 "102" 101 "101" 100 "100" 99 "99" 98 "98" 97 "97" 96 "96" 95 "95" 94 "94" 93 "93" 92 "92" 91 "91" 90 "90" 89 "89" 88 "88" 87 "87" 86 "86" 85 "85" 84 "84" 83 "83" 82 "82" 81 "81" 80 "80" 79 "79" 78 "78" 77 "77" 76 "76" 75 "75" 74 "74" 73 "73" 72 "72" 71 "71" 70 "70" 69 "69" 68 "68" 67 "67" 66 "66" 65 "65" 64 "64" 63 "63" 62 "62" 61 "61" 60 "60" 59 "59" 58 "58" 57 "57" 56 "56" 55 "55" 54 "54" 53 "53" 52 "52" 51 "51" 50 "50" 49 "49" 48 "48" 47 "47" 46 "46" 45 "45" 44 "44" 43 "43" 42 "42" 41 "41" 40 "40" 39 "39" 38 "38" 37 "37" 36 "36" 35 "35" 34 "34" 33 "33" 32 "32" 31 "31" 30 "30" 29 "29" 28 "28" 27 "27" 26 "26" 25 "25" 24 "24" 23 "23" 22 "22" 21 "21" 20 "20" 19 "19" 18 "18" 17 "17" 16 "16" 15 "15" 14 "14" 13 "13" 12 "12" 11 "11" 10 "10" 9 "9" 8 "8" 7 "7" 6 "6" 5 "5" 4 "4" 3 "3" 2 "2" 1 "1" 0 "Unknown" ;
VAL_ 656 DAS_LeftObj_3_Z_2_Val 81 "Error" 80 "80" 79 "79" 78 "78" 77 "77" 76 "76" 75 "75" 74 "74" 73 "73" 72 "72" 71 "71" 70 "70" 69 "69" 68 "68" 67 "67" 66 "66" 65 "65" 64 "64" 63 "63" 62 "62" 61 "61" 60 "60" 59 "59" 58 "58" 57 "57" 56 "56" 55 "55" 54 "54" 53 "53" 52 "52" 51 "51" 50 "50" 49 "49" 48 "48" 47 "47" 46 "46" 45 "45" 44 "44" 43 "43" 42 "42" 41 "41" 40 "40" 39 "39" 38 "38" 37 "37" 36 "36" 35 "35" 34 "34" 33 "33" 32 "32" 31 "31" 30 "30" 29 "29" 28 "28" 27 "27" 26 "26" 25 "25" 24 "24" 23 "23" 22 "22" 21 "21" 20 "20" 19 "19" 18 "18" 17 "17" 16 "16" 15 "15" 14 "14" 13 "13" 12 "12" 11 "11" 10 "10" 9 "9" 8 "8" 7 "7" 6 "6" 5 "5" 4 "4" 3 "3" 2 "2" 1 "1" 0 "Unknown" ;
VAL_ 656 DAS_ADBLeftLED3_Req 1 "On" 0 "Off" ;
VAL_ 656 DAS_ADBLeftLED10_Req 1 "On" 0 "Off" ;
VAL_ 656 DAS_LeftObj_10_Z_1_Val 81 "Error" 80 "80" 79 "79" 78 "78" 77 "77" 76 "76" 75 "75" 74 "74" 73 "73" 72 "72" 71 "71" 70 "70" 69 "69" 68 "68" 67 "67" 66 "66" 65 "65" 64 "64" 63 "63" 62 "62" 61 "61" 60 "60" 59 "59" 58 "58" 57 "57" 56 "56" 55 "55" 54 "54" 53 "53" 52 "52" 51 "51" 50 "50" 49 "49" 48 "48" 47 "47" 46 "46" 45 "45" 44 "44" 43 "43" 42 "42" 41 "41" 40 "40" 39 "39" 38 "38" 37 "37" 36 "36" 35 "35" 34 "34" 33 "33" 32 "32" 31 "31" 30 "30" 29 "29" 28 "28" 27 "27" 26 "26" 25 "25" 24 "24" 23 "23" 22 "22" 21 "21" 20 "20" 19 "19" 18 "18" 17 "17" 16 "16" 15 "15" 14 "14" 13 "13" 12 "12" 11 "11" 10 "10" 9 "9" 8 "8" 7 "7" 6 "6" 5 "5" 4 "4" 3 "3" 2 "2" 1 "1" 0 "Unknown" ;
VAL_ 656 DAS_LeftObj_8_Z_2_Val 81 "Error" 80 "80" 79 "79" 78 "78" 77 "77" 76 "76" 75 "75" 74 "74" 73 "73" 72 "72" 71 "71" 70 "70" 69 "69" 68 "68" 67 "67" 66 "66" 65 "65" 64 "64" 63 "63" 62 "62" 61 "61" 60 "60" 59 "59" 58 "58" 57 "57" 56 "56" 55 "55" 54 "54" 53 "53" 52 "52" 51 "51" 50 "50" 49 "49" 48 "48" 47 "47" 46 "46" 45 "45" 44 "44" 43 "43" 42 "42" 41 "41" 40 "40" 39 "39" 38 "38" 37 "37" 36 "36" 35 "35" 34 "34" 33 "33" 32 "32" 31 "31" 30 "30" 29 "29" 28 "28" 27 "27" 26 "26" 25 "25" 24 "24" 23 "23" 22 "22" 21 "21" 20 "20" 19 "19" 18 "18" 17 "17" 16 "16" 15 "15" 14 "14" 13 "13" 12 "12" 11 "11" 10 "10" 9 "9" 8 "8" 7 "7" 6 "6" 5 "5" 4 "4" 3 "3" 2 "2" 1 "1" 0 "Unknown" ;
VAL_ 656 DAS_ADBLeftLED15_Req 1 "On" 0 "Off" ;
VAL_ 656 DAS_LeftObj_4_Z_2_Val 81 "Error" 80 "80" 79 "79" 78 "78" 77 "77" 76 "76" 75 "75" 74 "74" 73 "73" 72 "72" 71 "71" 70 "70" 69 "69" 68 "68" 67 "67" 66 "66" 65 "65" 64 "64" 63 "63" 62 "62" 61 "61" 60 "60" 59 "59" 58 "58" 57 "57" 56 "56" 55 "55" 54 "54" 53 "53" 52 "52" 51 "51" 50 "50" 49 "49" 48 "48" 47 "47" 46 "46" 45 "45" 44 "44" 43 "43" 42 "42" 41 "41" 40 "40" 39 "39" 38 "38" 37 "37" 36 "36" 35 "35" 34 "34" 33 "33" 32 "32" 31 "31" 30 "30" 29 "29" 28 "28" 27 "27" 26 "26" 25 "25" 24 "24" 23 "23" 22 "22" 21 "21" 20 "20" 19 "19" 18 "18" 17 "17" 16 "16" 15 "15" 14 "14" 13 "13" 12 "12" 11 "11" 10 "10" 9 "9" 8 "8" 7 "7" 6 "6" 5 "5" 4 "4" 3 "3" 2 "2" 1 "1" 0 "Unknown" ;
VAL_ 656 DAS_ADBLeftLED1_Req 1 "On" 0 "Off" ;
VAL_ 656 DAS_ADBLeftLED16_Req 1 "On" 0 "Off" ;
VAL_ 656 DAS_LeftObj_7_Y_2_Val 321 "Error" 320 "320" 319 "319" 318 "318" 317 "317" 316 "316" 315 "315" 314 "314" 313 "313" 312 "312" 311 "311" 310 "310" 309 "309" 308 "308" 307 "307" 306 "306" 305 "305" 304 "304" 303 "303" 302 "302" 301 "301" 300 "300" 299 "299" 298 "298" 297 "297" 296 "296" 295 "295" 294 "294" 293 "293" 292 "292" 291 "291" 290 "290" 289 "289" 288 "288" 287 "287" 286 "286" 285 "285" 284 "284" 283 "283" 282 "282" 281 "281" 280 "280" 279 "279" 278 "278" 277 "277" 276 "276" 275 "275" 274 "274" 273 "273" 272 "272" 271 "271" 270 "270" 269 "269" 268 "268" 267 "267" 266 "266" 265 "265" 264 "264" 263 "263" 262 "262" 261 "261" 260 "260" 259 "259" 258 "258" 257 "257" 256 "256" 255 "255" 254 "254" 253 "253" 252 "252" 251 "251" 250 "250" 249 "249" 248 "248" 247 "247" 246 "246" 245 "245" 244 "244" 243 "243" 242 "242" 241 "241" 240 "240" 239 "239" 238 "238" 237 "237" 236 "236" 235 "235" 234 "234" 233 "233" 232 "232" 231 "231" 230 "230" 229 "229" 228 "228" 227 "227" 226 "226" 225 "225" 224 "224" 223 "223" 222 "222" 221 "221" 220 "220" 219 "219" 218 "218" 217 "217" 216 "216" 215 "215" 214 "214" 213 "213" 212 "212" 211 "211" 210 "210" 209 "209" 208 "208" 207 "207" 206 "206" 205 "205" 204 "204" 203 "203" 202 "202" 201 "201" 200 "200" 199 "199" 198 "198" 197 "197" 196 "196" 195 "195" 194 "194" 193 "193" 192 "192" 191 "191" 190 "190" 189 "189" 188 "188" 187 "187" 186 "186" 185 "185" 184 "184" 183 "183" 182 "182" 181 "181" 180 "180" 179 "179" 178 "178" 177 "177" 176 "176" 175 "175" 174 "174" 173 "173" 172 "172" 171 "171" 170 "170" 169 "169" 168 "168" 167 "167" 166 "166" 165 "165" 164 "164" 163 "163" 162 "162" 161 "161" 160 "160" 159 "159" 158 "158" 157 "157" 156 "156" 155 "155" 154 "154" 153 "153" 152 "152" 151 "151" 150 "150" 149 "149" 148 "148" 147 "147" 146 "146" 145 "145" 144 "144" 143 "143" 142 "142" 141 "141" 140 "140" 139 "139" 138 "138" 137 "137" 136 "136" 135 "135" 134 "134" 133 "133" 132 "132" 131 "131" 130 "130" 129 "129" 128 "128" 127 "127" 126 "126" 125 "125" 124 "124" 123 "123" 122 "122" 121 "121" 120 "120" 119 "119" 118 "118" 117 "117" 116 "116" 115 "115" 114 "114" 113 "113" 112 "112" 111 "111" 110 "110" 109 "109" 108 "108" 107 "107" 106 "106" 105 "105" 104 "104" 103 "103" 102 "102" 101 "101" 100 "100" 99 "99" 98 "98" 97 "97" 96 "96" 95 "95" 94 "94" 93 "93" 92 "92" 91 "91" 90 "90" 89 "89" 88 "88" 87 "87" 86 "86" 85 "85" 84 "84" 83 "83" 82 "82" 81 "81" 80 "80" 79 "79" 78 "78" 77 "77" 76 "76" 75 "75" 74 "74" 73 "73" 72 "72" 71 "71" 70 "70" 69 "69" 68 "68" 67 "67" 66 "66" 65 "65" 64 "64" 63 "63" 62 "62" 61 "61" 60 "60" 59 "59" 58 "58" 57 "57" 56 "56" 55 "55" 54 "54" 53 "53" 52 "52" 51 "51" 50 "50" 49 "49" 48 "48" 47 "47" 46 "46" 45 "45" 44 "44" 43 "43" 42 "42" 41 "41" 40 "40" 39 "39" 38 "38" 37 "37" 36 "36" 35 "35" 34 "34" 33 "33" 32 "32" 31 "31" 30 "30" 29 "29" 28 "28" 27 "27" 26 "26" 25 "25" 24 "24" 23 "23" 22 "22" 21 "21" 20 "20" 19 "19" 18 "18" 17 "17" 16 "16" 15 "15" 14 "14" 13 "13" 12 "12" 11 "11" 10 "10" 9 "9" 8 "8" 7 "7" 6 "6" 5 "5" 4 "4" 3 "3" 2 "2" 1 "1" 0 "Unknown" ;
VAL_ 656 DAS_LeftObj_2_Y_2_Val 321 "Error" 320 "320" 319 "319" 318 "318" 317 "317" 316 "316" 315 "315" 314 "314" 313 "313" 312 "312" 311 "311" 310 "310" 309 "309" 308 "308" 307 "307" 306 "306" 305 "305" 304 "304" 303 "303" 302 "302" 301 "301" 300 "300" 299 "299" 298 "298" 297 "297" 296 "296" 295 "295" 294 "294" 293 "293" 292 "292" 291 "291" 290 "290" 289 "289" 288 "288" 287 "287" 286 "286" 285 "285" 284 "284" 283 "283" 282 "282" 281 "281" 280 "280" 279 "279" 278 "278" 277 "277" 276 "276" 275 "275" 274 "274" 273 "273" 272 "272" 271 "271" 270 "270" 269 "269" 268 "268" 267 "267" 266 "266" 265 "265" 264 "264" 263 "263" 262 "262" 261 "261" 260 "260" 259 "259" 258 "258" 257 "257" 256 "256" 255 "255" 254 "254" 253 "253" 252 "252" 251 "251" 250 "250" 249 "249" 248 "248" 247 "247" 246 "246" 245 "245" 244 "244" 243 "243" 242 "242" 241 "241" 240 "240" 239 "239" 238 "238" 237 "237" 236 "236" 235 "235" 234 "234" 233 "233" 232 "232" 231 "231" 230 "230" 229 "229" 228 "228" 227 "227" 226 "226" 225 "225" 224 "224" 223 "223" 222 "222" 221 "221" 220 "220" 219 "219" 218 "218" 217 "217" 216 "216" 215 "215" 214 "214" 213 "213" 212 "212" 211 "211" 210 "210" 209 "209" 208 "208" 207 "207" 206 "206" 205 "205" 204 "204" 203 "203" 202 "202" 201 "201" 200 "200" 199 "199" 198 "198" 197 "197" 196 "196" 195 "195" 194 "194" 193 "193" 192 "192" 191 "191" 190 "190" 189 "189" 188 "188" 187 "187" 186 "186" 185 "185" 184 "184" 183 "183" 182 "182" 181 "181" 180 "180" 179 "179" 178 "178" 177 "177" 176 "176" 175 "175" 174 "174" 173 "173" 172 "172" 171 "171" 170 "170" 169 "169" 168 "168" 167 "167" 166 "166" 165 "165" 164 "164" 163 "163" 162 "162" 161 "161" 160 "160" 159 "159" 158 "158" 157 "157" 156 "156" 155 "155" 154 "154" 153 "153" 152 "152" 151 "151" 150 "150" 149 "149" 148 "148" 147 "147" 146 "146" 145 "145" 144 "144" 143 "143" 142 "142" 141 "141" 140 "140" 139 "139" 138 "138" 137 "137" 136 "136" 135 "135" 134 "134" 133 "133" 132 "132" 131 "131" 130 "130" 129 "129" 128 "128" 127 "127" 126 "126" 125 "125" 124 "124" 123 "123" 122 "122" 121 "121" 120 "120" 119 "119" 118 "118" 117 "117" 116 "116" 115 "115" 114 "114" 113 "113" 112 "112" 111 "111" 110 "110" 109 "109" 108 "108" 107 "107" 106 "106" 105 "105" 104 "104" 103 "103" 102 "102" 101 "101" 100 "100" 99 "99" 98 "98" 97 "97" 96 "96" 95 "95" 94 "94" 93 "93" 92 "92" 91 "91" 90 "90" 89 "89" 88 "88" 87 "87" 86 "86" 85 "85" 84 "84" 83 "83" 82 "82" 81 "81" 80 "80" 79 "79" 78 "78" 77 "77" 76 "76" 75 "75" 74 "74" 73 "73" 72 "72" 71 "71" 70 "70" 69 "69" 68 "68" 67 "67" 66 "66" 65 "65" 64 "64" 63 "63" 62 "62" 61 "61" 60 "60" 59 "59" 58 "58" 57 "57" 56 "56" 55 "55" 54 "54" 53 "53" 52 "52" 51 "51" 50 "50" 49 "49" 48 "48" 47 "47" 46 "46" 45 "45" 44 "44" 43 "43" 42 "42" 41 "41" 40 "40" 39 "39" 38 "38" 37 "37" 36 "36" 35 "35" 34 "34" 33 "33" 32 "32" 31 "31" 30 "30" 29 "29" 28 "28" 27 "27" 26 "26" 25 "25" 24 "24" 23 "23" 22 "22" 21 "21" 20 "20" 19 "19" 18 "18" 17 "17" 16 "16" 15 "15" 14 "14" 13 "13" 12 "12" 11 "11" 10 "10" 9 "9" 8 "8" 7 "7" 6 "6" 5 "5" 4 "4" 3 "3" 2 "2" 1 "1" 0 "Unknown" ;
VAL_ 656 DAS_LeftObj_10_Y_2_Val 321 "Error" 320 "320" 319 "319" 318 "318" 317 "317" 316 "316" 315 "315" 314 "314" 313 "313" 312 "312" 311 "311" 310 "310" 309 "309" 308 "308" 307 "307" 306 "306" 305 "305" 304 "304" 303 "303" 302 "302" 301 "301" 300 "300" 299 "299" 298 "298" 297 "297" 296 "296" 295 "295" 294 "294" 293 "293" 292 "292" 291 "291" 290 "290" 289 "289" 288 "288" 287 "287" 286 "286" 285 "285" 284 "284" 283 "283" 282 "282" 281 "281" 280 "280" 279 "279" 278 "278" 277 "277" 276 "276" 275 "275" 274 "274" 273 "273" 272 "272" 271 "271" 270 "270" 269 "269" 268 "268" 267 "267" 266 "266" 265 "265" 264 "264" 263 "263" 262 "262" 261 "261" 260 "260" 259 "259" 258 "258" 257 "257" 256 "256" 255 "255" 254 "254" 253 "253" 252 "252" 251 "251" 250 "250" 249 "249" 248 "248" 247 "247" 246 "246" 245 "245" 244 "244" 243 "243" 242 "242" 241 "241" 240 "240" 239 "239" 238 "238" 237 "237" 236 "236" 235 "235" 234 "234" 233 "233" 232 "232" 231 "231" 230 "230" 229 "229" 228 "228" 227 "227" 226 "226" 225 "225" 224 "224" 223 "223" 222 "222" 221 "221" 220 "220" 219 "219" 218 "218" 217 "217" 216 "216" 215 "215" 214 "214" 213 "213" 212 "212" 211 "211" 210 "210" 209 "209" 208 "208" 207 "207" 206 "206" 205 "205" 204 "204" 203 "203" 202 "202" 201 "201" 200 "200" 199 "199" 198 "198" 197 "197" 196 "196" 195 "195" 194 "194" 193 "193" 192 "192" 191 "191" 190 "190" 189 "189" 188 "188" 187 "187" 186 "186" 185 "185" 184 "184" 183 "183" 182 "182" 181 "181" 180 "180" 179 "179" 178 "178" 177 "177" 176 "176" 175 "175" 174 "174" 173 "173" 172 "172" 171 "171" 170 "170" 169 "169" 168 "168" 167 "167" 166 "166" 165 "165" 164 "164" 163 "163" 162 "162" 161 "161" 160 "160" 159 "159" 158 "158" 157 "157" 156 "156" 155 "155" 154 "154" 153 "153" 152 "152" 151 "151" 150 "150" 149 "149" 148 "148" 147 "147" 146 "146" 145 "145" 144 "144" 143 "143" 142 "142" 141 "141" 140 "140" 139 "139" 138 "138" 137 "137" 136 "136" 135 "135" 134 "134" 133 "133" 132 "132" 131 "131" 130 "130" 129 "129" 128 "128" 127 "127" 126 "126" 125 "125" 124 "124" 123 "123" 122 "122" 121 "121" 120 "120" 119 "119" 118 "118" 117 "117" 116 "116" 115 "115" 114 "114" 113 "113" 112 "112" 111 "111" 110 "110" 109 "109" 108 "108" 107 "107" 106 "106" 105 "105" 104 "104" 103 "103" 102 "102" 101 "101" 100 "100" 99 "99" 98 "98" 97 "97" 96 "96" 95 "95" 94 "94" 93 "93" 92 "92" 91 "91" 90 "90" 89 "89" 88 "88" 87 "87" 86 "86" 85 "85" 84 "84" 83 "83" 82 "82" 81 "81" 80 "80" 79 "79" 78 "78" 77 "77" 76 "76" 75 "75" 74 "74" 73 "73" 72 "72" 71 "71" 70 "70" 69 "69" 68 "68" 67 "67" 66 "66" 65 "65" 64 "64" 63 "63" 62 "62" 61 "61" 60 "60" 59 "59" 58 "58" 57 "57" 56 "56" 55 "55" 54 "54" 53 "53" 52 "52" 51 "51" 50 "50" 49 "49" 48 "48" 47 "47" 46 "46" 45 "45" 44 "44" 43 "43" 42 "42" 41 "41" 40 "40" 39 "39" 38 "38" 37 "37" 36 "36" 35 "35" 34 "34" 33 "33" 32 "32" 31 "31" 30 "30" 29 "29" 28 "28" 27 "27" 26 "26" 25 "25" 24 "24" 23 "23" 22 "22" 21 "21" 20 "20" 19 "19" 18 "18" 17 "17" 16 "16" 15 "15" 14 "14" 13 "13" 12 "12" 11 "11" 10 "10" 9 "9" 8 "8" 7 "7" 6 "6" 5 "5" 4 "4" 3 "3" 2 "2" 1 "1" 0 "Unknown" ;
VAL_ 656 DAS_LeftObj_8_Z_1_Val 81 "Error" 80 "80" 79 "79" 78 "78" 77 "77" 76 "76" 75 "75" 74 "74" 73 "73" 72 "72" 71 "71" 70 "70" 69 "69" 68 "68" 67 "67" 66 "66" 65 "65" 64 "64" 63 "63" 62 "62" 61 "61" 60 "60" 59 "59" 58 "58" 57 "57" 56 "56" 55 "55" 54 "54" 53 "53" 52 "52" 51 "51" 50 "50" 49 "49" 48 "48" 47 "47" 46 "46" 45 "45" 44 "44" 43 "43" 42 "42" 41 "41" 40 "40" 39 "39" 38 "38" 37 "37" 36 "36" 35 "35" 34 "34" 33 "33" 32 "32" 31 "31" 30 "30" 29 "29" 28 "28" 27 "27" 26 "26" 25 "25" 24 "24" 23 "23" 22 "22" 21 "21" 20 "20" 19 "19" 18 "18" 17 "17" 16 "16" 15 "15" 14 "14" 13 "13" 12 "12" 11 "11" 10 "10" 9 "9" 8 "8" 7 "7" 6 "6" 5 "5" 4 "4" 3 "3" 2 "2" 1 "1" 0 "Unknown" ;
VAL_ 656 DAS_LeftObj_9_Y_1_Val 321 "Error" 320 "320" 319 "319" 318 "318" 317 "317" 316 "316" 315 "315" 314 "314" 313 "313" 312 "312" 311 "311" 310 "310" 309 "309" 308 "308" 307 "307" 306 "306" 305 "305" 304 "304" 303 "303" 302 "302" 301 "301" 300 "300" 299 "299" 298 "298" 297 "297" 296 "296" 295 "295" 294 "294" 293 "293" 292 "292" 291 "291" 290 "290" 289 "289" 288 "288" 287 "287" 286 "286" 285 "285" 284 "284" 283 "283" 282 "282" 281 "281" 280 "280" 279 "279" 278 "278" 277 "277" 276 "276" 275 "275" 274 "274" 273 "273" 272 "272" 271 "271" 270 "270" 269 "269" 268 "268" 267 "267" 266 "266" 265 "265" 264 "264" 263 "263" 262 "262" 261 "261" 260 "260" 259 "259" 258 "258" 257 "257" 256 "256" 255 "255" 254 "254" 253 "253" 252 "252" 251 "251" 250 "250" 249 "249" 248 "248" 247 "247" 246 "246" 245 "245" 244 "244" 243 "243" 242 "242" 241 "241" 240 "240" 239 "239" 238 "238" 237 "237" 236 "236" 235 "235" 234 "234" 233 "233" 232 "232" 231 "231" 230 "230" 229 "229" 228 "228" 227 "227" 226 "226" 225 "225" 224 "224" 223 "223" 222 "222" 221 "221" 220 "220" 219 "219" 218 "218" 217 "217" 216 "216" 215 "215" 214 "214" 213 "213" 212 "212" 211 "211" 210 "210" 209 "209" 208 "208" 207 "207" 206 "206" 205 "205" 204 "204" 203 "203" 202 "202" 201 "201" 200 "200" 199 "199" 198 "198" 197 "197" 196 "196" 195 "195" 194 "194" 193 "193" 192 "192" 191 "191" 190 "190" 189 "189" 188 "188" 187 "187" 186 "186" 185 "185" 184 "184" 183 "183" 182 "182" 181 "181" 180 "180" 179 "179" 178 "178" 177 "177" 176 "176" 175 "175" 174 "174" 173 "173" 172 "172" 171 "171" 170 "170" 169 "169" 168 "168" 167 "167" 166 "166" 165 "165" 164 "164" 163 "163" 162 "162" 161 "161" 160 "160" 159 "159" 158 "158" 157 "157" 156 "156" 155 "155" 154 "154" 153 "153" 152 "152" 151 "151" 150 "150" 149 "149" 148 "148" 147 "147" 146 "146" 145 "145" 144 "144" 143 "143" 142 "142" 141 "141" 140 "140" 139 "139" 138 "138" 137 "137" 136 "136" 135 "135" 134 "134" 133 "133" 132 "132" 131 "131" 130 "130" 129 "129" 128 "128" 127 "127" 126 "126" 125 "125" 124 "124" 123 "123" 122 "122" 121 "121" 120 "120" 119 "119" 118 "118" 117 "117" 116 "116" 115 "115" 114 "114" 113 "113" 112 "112" 111 "111" 110 "110" 109 "109" 108 "108" 107 "107" 106 "106" 105 "105" 104 "104" 103 "103" 102 "102" 101 "101" 100 "100" 99 "99" 98 "98" 97 "97" 96 "96" 95 "95" 94 "94" 93 "93" 92 "92" 91 "91" 90 "90" 89 "89" 88 "88" 87 "87" 86 "86" 85 "85" 84 "84" 83 "83" 82 "82" 81 "81" 80 "80" 79 "79" 78 "78" 77 "77" 76 "76" 75 "75" 74 "74" 73 "73" 72 "72" 71 "71" 70 "70" 69 "69" 68 "68" 67 "67" 66 "66" 65 "65" 64 "64" 63 "63" 62 "62" 61 "61" 60 "60" 59 "59" 58 "58" 57 "57" 56 "56" 55 "55" 54 "54" 53 "53" 52 "52" 51 "51" 50 "50" 49 "49" 48 "48" 47 "47" 46 "46" 45 "45" 44 "44" 43 "43" 42 "42" 41 "41" 40 "40" 39 "39" 38 "38" 37 "37" 36 "36" 35 "35" 34 "34" 33 "33" 32 "32" 31 "31" 30 "30" 29 "29" 28 "28" 27 "27" 26 "26" 25 "25" 24 "24" 23 "23" 22 "22" 21 "21" 20 "20" 19 "19" 18 "18" 17 "17" 16 "16" 15 "15" 14 "14" 13 "13" 12 "12" 11 "11" 10 "10" 9 "9" 8 "8" 7 "7" 6 "6" 5 "5" 4 "4" 3 "3" 2 "2" 1 "1" 0 "Unknown" ;
VAL_ 656 DAS_LeftObj_8_Y_2_Val 321 "Error" 320 "320" 319 "319" 318 "318" 317 "317" 316 "316" 315 "315" 314 "314" 313 "313" 312 "312" 311 "311" 310 "310" 309 "309" 308 "308" 307 "307" 306 "306" 305 "305" 304 "304" 303 "303" 302 "302" 301 "301" 300 "300" 299 "299" 298 "298" 297 "297" 296 "296" 295 "295" 294 "294" 293 "293" 292 "292" 291 "291" 290 "290" 289 "289" 288 "288" 287 "287" 286 "286" 285 "285" 284 "284" 283 "283" 282 "282" 281 "281" 280 "280" 279 "279" 278 "278" 277 "277" 276 "276" 275 "275" 274 "274" 273 "273" 272 "272" 271 "271" 270 "270" 269 "269" 268 "268" 267 "267" 266 "266" 265 "265" 264 "264" 263 "263" 262 "262" 261 "261" 260 "260" 259 "259" 258 "258" 257 "257" 256 "256" 255 "255" 254 "254" 253 "253" 252 "252" 251 "251" 250 "250" 249 "249" 248 "248" 247 "247" 246 "246" 245 "245" 244 "244" 243 "243" 242 "242" 241 "241" 240 "240" 239 "239" 238 "238" 237 "237" 236 "236" 235 "235" 234 "234" 233 "233" 232 "232" 231 "231" 230 "230" 229 "229" 228 "228" 227 "227" 226 "226" 225 "225" 224 "224" 223 "223" 222 "222" 221 "221" 220 "220" 219 "219" 218 "218" 217 "217" 216 "216" 215 "215" 214 "214" 213 "213" 212 "212" 211 "211" 210 "210" 209 "209" 208 "208" 207 "207" 206 "206" 205 "205" 204 "204" 203 "203" 202 "202" 201 "201" 200 "200" 199 "199" 198 "198" 197 "197" 196 "196" 195 "195" 194 "194" 193 "193" 192 "192" 191 "191" 190 "190" 189 "189" 188 "188" 187 "187" 186 "186" 185 "185" 184 "184" 183 "183" 182 "182" 181 "181" 180 "180" 179 "179" 178 "178" 177 "177" 176 "176" 175 "175" 174 "174" 173 "173" 172 "172" 171 "171" 170 "170" 169 "169" 168 "168" 167 "167" 166 "166" 165 "165" 164 "164" 163 "163" 162 "162" 161 "161" 160 "160" 159 "159" 158 "158" 157 "157" 156 "156" 155 "155" 154 "154" 153 "153" 152 "152" 151 "151" 150 "150" 149 "149" 148 "148" 147 "147" 146 "146" 145 "145" 144 "144" 143 "143" 142 "142" 141 "141" 140 "140" 139 "139" 138 "138" 137 "137" 136 "136" 135 "135" 134 "134" 133 "133" 132 "132" 131 "131" 130 "130" 129 "129" 128 "128" 127 "127" 126 "126" 125 "125" 124 "124" 123 "123" 122 "122" 121 "121" 120 "120" 119 "119" 118 "118" 117 "117" 116 "116" 115 "115" 114 "114" 113 "113" 112 "112" 111 "111" 110 "110" 109 "109" 108 "108" 107 "107" 106 "106" 105 "105" 104 "104" 103 "103" 102 "102" 101 "101" 100 "100" 99 "99" 98 "98" 97 "97" 96 "96" 95 "95" 94 "94" 93 "93" 92 "92" 91 "91" 90 "90" 89 "89" 88 "88" 87 "87" 86 "86" 85 "85" 84 "84" 83 "83" 82 "82" 81 "81" 80 "80" 79 "79" 78 "78" 77 "77" 76 "76" 75 "75" 74 "74" 73 "73" 72 "72" 71 "71" 70 "70" 69 "69" 68 "68" 67 "67" 66 "66" 65 "65" 64 "64" 63 "63" 62 "62" 61 "61" 60 "60" 59 "59" 58 "58" 57 "57" 56 "56" 55 "55" 54 "54" 53 "53" 52 "52" 51 "51" 50 "50" 49 "49" 48 "48" 47 "47" 46 "46" 45 "45" 44 "44" 43 "43" 42 "42" 41 "41" 40 "40" 39 "39" 38 "38" 37 "37" 36 "36" 35 "35" 34 "34" 33 "33" 32 "32" 31 "31" 30 "30" 29 "29" 28 "28" 27 "27" 26 "26" 25 "25" 24 "24" 23 "23" 22 "22" 21 "21" 20 "20" 19 "19" 18 "18" 17 "17" 16 "16" 15 "15" 14 "14" 13 "13" 12 "12" 11 "11" 10 "10" 9 "9" 8 "8" 7 "7" 6 "6" 5 "5" 4 "4" 3 "3" 2 "2" 1 "1" 0 "Unknown" ;
VAL_ 656 DAS_LeftObj_4_Z_1_Val 81 "Error" 80 "80" 79 "79" 78 "78" 77 "77" 76 "76" 75 "75" 74 "74" 73 "73" 72 "72" 71 "71" 70 "70" 69 "69" 68 "68" 67 "67" 66 "66" 65 "65" 64 "64" 63 "63" 62 "62" 61 "61" 60 "60" 59 "59" 58 "58" 57 "57" 56 "56" 55 "55" 54 "54" 53 "53" 52 "52" 51 "51" 50 "50" 49 "49" 48 "48" 47 "47" 46 "46" 45 "45" 44 "44" 43 "43" 42 "42" 41 "41" 40 "40" 39 "39" 38 "38" 37 "37" 36 "36" 35 "35" 34 "34" 33 "33" 32 "32" 31 "31" 30 "30" 29 "29" 28 "28" 27 "27" 26 "26" 25 "25" 24 "24" 23 "23" 22 "22" 21 "21" 20 "20" 19 "19" 18 "18" 17 "17" 16 "16" 15 "15" 14 "14" 13 "13" 12 "12" 11 "11" 10 "10" 9 "9" 8 "8" 7 "7" 6 "6" 5 "5" 4 "4" 3 "3" 2 "2" 1 "1" 0 "Unknown" ;
VAL_ 656 DAS_LeftObj_2_Z_2_Val 81 "Error" 80 "80" 79 "79" 78 "78" 77 "77" 76 "76" 75 "75" 74 "74" 73 "73" 72 "72" 71 "71" 70 "70" 69 "69" 68 "68" 67 "67" 66 "66" 65 "65" 64 "64" 63 "63" 62 "62" 61 "61" 60 "60" 59 "59" 58 "58" 57 "57" 56 "56" 55 "55" 54 "54" 53 "53" 52 "52" 51 "51" 50 "50" 49 "49" 48 "48" 47 "47" 46 "46" 45 "45" 44 "44" 43 "43" 42 "42" 41 "41" 40 "40" 39 "39" 38 "38" 37 "37" 36 "36" 35 "35" 34 "34" 33 "33" 32 "32" 31 "31" 30 "30" 29 "29" 28 "28" 27 "27" 26 "26" 25 "25" 24 "24" 23 "23" 22 "22" 21 "21" 20 "20" 19 "19" 18 "18" 17 "17" 16 "16" 15 "15" 14 "14" 13 "13" 12 "12" 11 "11" 10 "10" 9 "9" 8 "8" 7 "7" 6 "6" 5 "5" 4 "4" 3 "3" 2 "2" 1 "1" 0 "Unknown" ;
VAL_ 656 DAS_LeftObj_8_Y_1_Val 321 "Error" 320 "320" 319 "319" 318 "318" 317 "317" 316 "316" 315 "315" 314 "314" 313 "313" 312 "312" 311 "311" 310 "310" 309 "309" 308 "308" 307 "307" 306 "306" 305 "305" 304 "304" 303 "303" 302 "302" 301 "301" 300 "300" 299 "299" 298 "298" 297 "297" 296 "296" 295 "295" 294 "294" 293 "293" 292 "292" 291 "291" 290 "290" 289 "289" 288 "288" 287 "287" 286 "286" 285 "285" 284 "284" 283 "283" 282 "282" 281 "281" 280 "280" 279 "279" 278 "278" 277 "277" 276 "276" 275 "275" 274 "274" 273 "273" 272 "272" 271 "271" 270 "270" 269 "269" 268 "268" 267 "267" 266 "266" 265 "265" 264 "264" 263 "263" 262 "262" 261 "261" 260 "260" 259 "259" 258 "258" 257 "257" 256 "256" 255 "255" 254 "254" 253 "253" 252 "252" 251 "251" 250 "250" 249 "249" 248 "248" 247 "247" 246 "246" 245 "245" 244 "244" 243 "243" 242 "242" 241 "241" 240 "240" 239 "239" 238 "238" 237 "237" 236 "236" 235 "235" 234 "234" 233 "233" 232 "232" 231 "231" 230 "230" 229 "229" 228 "228" 227 "227" 226 "226" 225 "225" 224 "224" 223 "223" 222 "222" 221 "221" 220 "220" 219 "219" 218 "218" 217 "217" 216 "216" 215 "215" 214 "214" 213 "213" 212 "212" 211 "211" 210 "210" 209 "209" 208 "208" 207 "207" 206 "206" 205 "205" 204 "204" 203 "203" 202 "202" 201 "201" 200 "200" 199 "199" 198 "198" 197 "197" 196 "196" 195 "195" 194 "194" 193 "193" 192 "192" 191 "191" 190 "190" 189 "189" 188 "188" 187 "187" 186 "186" 185 "185" 184 "184" 183 "183" 182 "182" 181 "181" 180 "180" 179 "179" 178 "178" 177 "177" 176 "176" 175 "175" 174 "174" 173 "173" 172 "172" 171 "171" 170 "170" 169 "169" 168 "168" 167 "167" 166 "166" 165 "165" 164 "164" 163 "163" 162 "162" 161 "161" 160 "160" 159 "159" 158 "158" 157 "157" 156 "156" 155 "155" 154 "154" 153 "153" 152 "152" 151 "151" 150 "150" 149 "149" 148 "148" 147 "147" 146 "146" 145 "145" 144 "144" 143 "143" 142 "142" 141 "141" 140 "140" 139 "139" 138 "138" 137 "137" 136 "136" 135 "135" 134 "134" 133 "133" 132 "132" 131 "131" 130 "130" 129 "129" 128 "128" 127 "127" 126 "126" 125 "125" 124 "124" 123 "123" 122 "122" 121 "121" 120 "120" 119 "119" 118 "118" 117 "117" 116 "116" 115 "115" 114 "114" 113 "113" 112 "112" 111 "111" 110 "110" 109 "109" 108 "108" 107 "107" 106 "106" 105 "105" 104 "104" 103 "103" 102 "102" 101 "101" 100 "100" 99 "99" 98 "98" 97 "97" 96 "96" 95 "95" 94 "94" 93 "93" 92 "92" 91 "91" 90 "90" 89 "89" 88 "88" 87 "87" 86 "86" 85 "85" 84 "84" 83 "83" 82 "82" 81 "81" 80 "80" 79 "79" 78 "78" 77 "77" 76 "76" 75 "75" 74 "74" 73 "73" 72 "72" 71 "71" 70 "70" 69 "69" 68 "68" 67 "67" 66 "66" 65 "65" 64 "64" 63 "63" 62 "62" 61 "61" 60 "60" 59 "59" 58 "58" 57 "57" 56 "56" 55 "55" 54 "54" 53 "53" 52 "52" 51 "51" 50 "50" 49 "49" 48 "48" 47 "47" 46 "46" 45 "45" 44 "44" 43 "43" 42 "42" 41 "41" 40 "40" 39 "39" 38 "38" 37 "37" 36 "36" 35 "35" 34 "34" 33 "33" 32 "32" 31 "31" 30 "30" 29 "29" 28 "28" 27 "27" 26 "26" 25 "25" 24 "24" 23 "23" 22 "22" 21 "21" 20 "20" 19 "19" 18 "18" 17 "17" 16 "16" 15 "15" 14 "14" 13 "13" 12 "12" 11 "11" 10 "10" 9 "9" 8 "8" 7 "7" 6 "6" 5 "5" 4 "4" 3 "3" 2 "2" 1 "1" 0 "Unknown" ;
VAL_ 656 DAS_LeftObj_1_Y_1_Val 321 "Error" 320 "320" 319 "319" 318 "318" 317 "317" 316 "316" 315 "315" 314 "314" 313 "313" 312 "312" 311 "311" 310 "310" 309 "309" 308 "308" 307 "307" 306 "306" 305 "305" 304 "304" 303 "303" 302 "302" 301 "301" 300 "300" 299 "299" 298 "298" 297 "297" 296 "296" 295 "295" 294 "294" 293 "293" 292 "292" 291 "291" 290 "290" 289 "289" 288 "288" 287 "287" 286 "286" 285 "285" 284 "284" 283 "283" 282 "282" 281 "281" 280 "280" 279 "279" 278 "278" 277 "277" 276 "276" 275 "275" 274 "274" 273 "273" 272 "272" 271 "271" 270 "270" 269 "269" 268 "268" 267 "267" 266 "266" 265 "265" 264 "264" 263 "263" 262 "262" 261 "261" 260 "260" 259 "259" 258 "258" 257 "257" 256 "256" 255 "255" 254 "254" 253 "253" 252 "252" 251 "251" 250 "250" 249 "249" 248 "248" 247 "247" 246 "246" 245 "245" 244 "244" 243 "243" 242 "242" 241 "241" 240 "240" 239 "239" 238 "238" 237 "237" 236 "236" 235 "235" 234 "234" 233 "233" 232 "232" 231 "231" 230 "230" 229 "229" 228 "228" 227 "227" 226 "226" 225 "225" 224 "224" 223 "223" 222 "222" 221 "221" 220 "220" 219 "219" 218 "218" 217 "217" 216 "216" 215 "215" 214 "214" 213 "213" 212 "212" 211 "211" 210 "210" 209 "209" 208 "208" 207 "207" 206 "206" 205 "205" 204 "204" 203 "203" 202 "202" 201 "201" 200 "200" 199 "199" 198 "198" 197 "197" 196 "196" 195 "195" 194 "194" 193 "193" 192 "192" 191 "191" 190 "190" 189 "189" 188 "188" 187 "187" 186 "186" 185 "185" 184 "184" 183 "183" 182 "182" 181 "181" 180 "180" 179 "179" 178 "178" 177 "177" 176 "176" 175 "175" 174 "174" 173 "173" 172 "172" 171 "171" 170 "170" 169 "169" 168 "168" 167 "167" 166 "166" 165 "165" 164 "164" 163 "163" 162 "162" 161 "161" 160 "160" 159 "159" 158 "158" 157 "157" 156 "156" 155 "155" 154 "154" 153 "153" 152 "152" 151 "151" 150 "150" 149 "149" 148 "148" 147 "147" 146 "146" 145 "145" 144 "144" 143 "143" 142 "142" 141 "141" 140 "140" 139 "139" 138 "138" 137 "137" 136 "136" 135 "135" 134 "134" 133 "133" 132 "132" 131 "131" 130 "130" 129 "129" 128 "128" 127 "127" 126 "126" 125 "125" 124 "124" 123 "123" 122 "122" 121 "121" 120 "120" 119 "119" 118 "118" 117 "117" 116 "116" 115 "115" 114 "114" 113 "113" 112 "112" 111 "111" 110 "110" 109 "109" 108 "108" 107 "107" 106 "106" 105 "105" 104 "104" 103 "103" 102 "102" 101 "101" 100 "100" 99 "99" 98 "98" 97 "97" 96 "96" 95 "95" 94 "94" 93 "93" 92 "92" 91 "91" 90 "90" 89 "89" 88 "88" 87 "87" 86 "86" 85 "85" 84 "84" 83 "83" 82 "82" 81 "81" 80 "80" 79 "79" 78 "78" 77 "77" 76 "76" 75 "75" 74 "74" 73 "73" 72 "72" 71 "71" 70 "70" 69 "69" 68 "68" 67 "67" 66 "66" 65 "65" 64 "64" 63 "63" 62 "62" 61 "61" 60 "60" 59 "59" 58 "58" 57 "57" 56 "56" 55 "55" 54 "54" 53 "53" 52 "52" 51 "51" 50 "50" 49 "49" 48 "48" 47 "47" 46 "46" 45 "45" 44 "44" 43 "43" 42 "42" 41 "41" 40 "40" 39 "39" 38 "38" 37 "37" 36 "36" 35 "35" 34 "34" 33 "33" 32 "32" 31 "31" 30 "30" 29 "29" 28 "28" 27 "27" 26 "26" 25 "25" 24 "24" 23 "23" 22 "22" 21 "21" 20 "20" 19 "19" 18 "18" 17 "17" 16 "16" 15 "15" 14 "14" 13 "13" 12 "12" 11 "11" 10 "10" 9 "9" 8 "8" 7 "7" 6 "6" 5 "5" 4 "4" 3 "3" 2 "2" 1 "1" 0 "Unknown" ;
VAL_ 656 DAS_LeftObj_4_Y_2_Val 321 "Error" 320 "320" 319 "319" 318 "318" 317 "317" 316 "316" 315 "315" 314 "314" 313 "313" 312 "312" 311 "311" 310 "310" 309 "309" 308 "308" 307 "307" 306 "306" 305 "305" 304 "304" 303 "303" 302 "302" 301 "301" 300 "300" 299 "299" 298 "298" 297 "297" 296 "296" 295 "295" 294 "294" 293 "293" 292 "292" 291 "291" 290 "290" 289 "289" 288 "288" 287 "287" 286 "286" 285 "285" 284 "284" 283 "283" 282 "282" 281 "281" 280 "280" 279 "279" 278 "278" 277 "277" 276 "276" 275 "275" 274 "274" 273 "273" 272 "272" 271 "271" 270 "270" 269 "269" 268 "268" 267 "267" 266 "266" 265 "265" 264 "264" 263 "263" 262 "262" 261 "261" 260 "260" 259 "259" 258 "258" 257 "257" 256 "256" 255 "255" 254 "254" 253 "253" 252 "252" 251 "251" 250 "250" 249 "249" 248 "248" 247 "247" 246 "246" 245 "245" 244 "244" 243 "243" 242 "242" 241 "241" 240 "240" 239 "239" 238 "238" 237 "237" 236 "236" 235 "235" 234 "234" 233 "233" 232 "232" 231 "231" 230 "230" 229 "229" 228 "228" 227 "227" 226 "226" 225 "225" 224 "224" 223 "223" 222 "222" 221 "221" 220 "220" 219 "219" 218 "218" 217 "217" 216 "216" 215 "215" 214 "214" 213 "213" 212 "212" 211 "211" 210 "210" 209 "209" 208 "208" 207 "207" 206 "206" 205 "205" 204 "204" 203 "203" 202 "202" 201 "201" 200 "200" 199 "199" 198 "198" 197 "197" 196 "196" 195 "195" 194 "194" 193 "193" 192 "192" 191 "191" 190 "190" 189 "189" 188 "188" 187 "187" 186 "186" 185 "185" 184 "184" 183 "183" 182 "182" 181 "181" 180 "180" 179 "179" 178 "178" 177 "177" 176 "176" 175 "175" 174 "174" 173 "173" 172 "172" 171 "171" 170 "170" 169 "169" 168 "168" 167 "167" 166 "166" 165 "165" 164 "164" 163 "163" 162 "162" 161 "161" 160 "160" 159 "159" 158 "158" 157 "157" 156 "156" 155 "155" 154 "154" 153 "153" 152 "152" 151 "151" 150 "150" 149 "149" 148 "148" 147 "147" 146 "146" 145 "145" 144 "144" 143 "143" 142 "142" 141 "141" 140 "140" 139 "139" 138 "138" 137 "137" 136 "136" 135 "135" 134 "134" 133 "133" 132 "132" 131 "131" 130 "130" 129 "129" 128 "128" 127 "127" 126 "126" 125 "125" 124 "124" 123 "123" 122 "122" 121 "121" 120 "120" 119 "119" 118 "118" 117 "117" 116 "116" 115 "115" 114 "114" 113 "113" 112 "112" 111 "111" 110 "110" 109 "109" 108 "108" 107 "107" 106 "106" 105 "105" 104 "104" 103 "103" 102 "102" 101 "101" 100 "100" 99 "99" 98 "98" 97 "97" 96 "96" 95 "95" 94 "94" 93 "93" 92 "92" 91 "91" 90 "90" 89 "89" 88 "88" 87 "87" 86 "86" 85 "85" 84 "84" 83 "83" 82 "82" 81 "81" 80 "80" 79 "79" 78 "78" 77 "77" 76 "76" 75 "75" 74 "74" 73 "73" 72 "72" 71 "71" 70 "70" 69 "69" 68 "68" 67 "67" 66 "66" 65 "65" 64 "64" 63 "63" 62 "62" 61 "61" 60 "60" 59 "59" 58 "58" 57 "57" 56 "56" 55 "55" 54 "54" 53 "53" 52 "52" 51 "51" 50 "50" 49 "49" 48 "48" 47 "47" 46 "46" 45 "45" 44 "44" 43 "43" 42 "42" 41 "41" 40 "40" 39 "39" 38 "38" 37 "37" 36 "36" 35 "35" 34 "34" 33 "33" 32 "32" 31 "31" 30 "30" 29 "29" 28 "28" 27 "27" 26 "26" 25 "25" 24 "24" 23 "23" 22 "22" 21 "21" 20 "20" 19 "19" 18 "18" 17 "17" 16 "16" 15 "15" 14 "14" 13 "13" 12 "12" 11 "11" 10 "10" 9 "9" 8 "8" 7 "7" 6 "6" 5 "5" 4 "4" 3 "3" 2 "2" 1 "1" 0 "Unknown" ;
VAL_ 656 DAS_LeftObj_4_Y_1_Val 321 "Error" 320 "320" 319 "319" 318 "318" 317 "317" 316 "316" 315 "315" 314 "314" 313 "313" 312 "312" 311 "311" 310 "310" 309 "309" 308 "308" 307 "307" 306 "306" 305 "305" 304 "304" 303 "303" 302 "302" 301 "301" 300 "300" 299 "299" 298 "298" 297 "297" 296 "296" 295 "295" 294 "294" 293 "293" 292 "292" 291 "291" 290 "290" 289 "289" 288 "288" 287 "287" 286 "286" 285 "285" 284 "284" 283 "283" 282 "282" 281 "281" 280 "280" 279 "279" 278 "278" 277 "277" 276 "276" 275 "275" 274 "274" 273 "273" 272 "272" 271 "271" 270 "270" 269 "269" 268 "268" 267 "267" 266 "266" 265 "265" 264 "264" 263 "263" 262 "262" 261 "261" 260 "260" 259 "259" 258 "258" 257 "257" 256 "256" 255 "255" 254 "254" 253 "253" 252 "252" 251 "251" 250 "250" 249 "249" 248 "248" 247 "247" 246 "246" 245 "245" 244 "244" 243 "243" 242 "242" 241 "241" 240 "240" 239 "239" 238 "238" 237 "237" 236 "236" 235 "235" 234 "234" 233 "233" 232 "232" 231 "231" 230 "230" 229 "229" 228 "228" 227 "227" 226 "226" 225 "225" 224 "224" 223 "223" 222 "222" 221 "221" 220 "220" 219 "219" 218 "218" 217 "217" 216 "216" 215 "215" 214 "214" 213 "213" 212 "212" 211 "211" 210 "210" 209 "209" 208 "208" 207 "207" 206 "206" 205 "205" 204 "204" 203 "203" 202 "202" 201 "201" 200 "200" 199 "199" 198 "198" 197 "197" 196 "196" 195 "195" 194 "194" 193 "193" 192 "192" 191 "191" 190 "190" 189 "189" 188 "188" 187 "187" 186 "186" 185 "185" 184 "184" 183 "183" 182 "182" 181 "181" 180 "180" 179 "179" 178 "178" 177 "177" 176 "176" 175 "175" 174 "174" 173 "173" 172 "172" 171 "171" 170 "170" 169 "169" 168 "168" 167 "167" 166 "166" 165 "165" 164 "164" 163 "163" 162 "162" 161 "161" 160 "160" 159 "159" 158 "158" 157 "157" 156 "156" 155 "155" 154 "154" 153 "153" 152 "152" 151 "151" 150 "150" 149 "149" 148 "148" 147 "147" 146 "146" 145 "145" 144 "144" 143 "143" 142 "142" 141 "141" 140 "140" 139 "139" 138 "138" 137 "137" 136 "136" 135 "135" 134 "134" 133 "133" 132 "132" 131 "131" 130 "130" 129 "129" 128 "128" 127 "127" 126 "126" 125 "125" 124 "124" 123 "123" 122 "122" 121 "121" 120 "120" 119 "119" 118 "118" 117 "117" 116 "116" 115 "115" 114 "114" 113 "113" 112 "112" 111 "111" 110 "110" 109 "109" 108 "108" 107 "107" 106 "106" 105 "105" 104 "104" 103 "103" 102 "102" 101 "101" 100 "100" 99 "99" 98 "98" 97 "97" 96 "96" 95 "95" 94 "94" 93 "93" 92 "92" 91 "91" 90 "90" 89 "89" 88 "88" 87 "87" 86 "86" 85 "85" 84 "84" 83 "83" 82 "82" 81 "81" 80 "80" 79 "79" 78 "78" 77 "77" 76 "76" 75 "75" 74 "74" 73 "73" 72 "72" 71 "71" 70 "70" 69 "69" 68 "68" 67 "67" 66 "66" 65 "65" 64 "64" 63 "63" 62 "62" 61 "61" 60 "60" 59 "59" 58 "58" 57 "57" 56 "56" 55 "55" 54 "54" 53 "53" 52 "52" 51 "51" 50 "50" 49 "49" 48 "48" 47 "47" 46 "46" 45 "45" 44 "44" 43 "43" 42 "42" 41 "41" 40 "40" 39 "39" 38 "38" 37 "37" 36 "36" 35 "35" 34 "34" 33 "33" 32 "32" 31 "31" 30 "30" 29 "29" 28 "28" 27 "27" 26 "26" 25 "25" 24 "24" 23 "23" 22 "22" 21 "21" 20 "20" 19 "19" 18 "18" 17 "17" 16 "16" 15 "15" 14 "14" 13 "13" 12 "12" 11 "11" 10 "10" 9 "9" 8 "8" 7 "7" 6 "6" 5 "5" 4 "4" 3 "3" 2 "2" 1 "1" 0 "Unknown" ;
VAL_ 656 DAS_ADBLeftLED5_Req 1 "On" 0 "Off" ;
VAL_ 656 DAS_ADBLeftLED7_Req 1 "On" 0 "Off" ;
VAL_ 656 DAS_LeftObj_5_Z_1_Val 81 "Error" 80 "80" 79 "79" 78 "78" 77 "77" 76 "76" 75 "75" 74 "74" 73 "73" 72 "72" 71 "71" 70 "70" 69 "69" 68 "68" 67 "67" 66 "66" 65 "65" 64 "64" 63 "63" 62 "62" 61 "61" 60 "60" 59 "59" 58 "58" 57 "57" 56 "56" 55 "55" 54 "54" 53 "53" 52 "52" 51 "51" 50 "50" 49 "49" 48 "48" 47 "47" 46 "46" 45 "45" 44 "44" 43 "43" 42 "42" 41 "41" 40 "40" 39 "39" 38 "38" 37 "37" 36 "36" 35 "35" 34 "34" 33 "33" 32 "32" 31 "31" 30 "30" 29 "29" 28 "28" 27 "27" 26 "26" 25 "25" 24 "24" 23 "23" 22 "22" 21 "21" 20 "20" 19 "19" 18 "18" 17 "17" 16 "16" 15 "15" 14 "14" 13 "13" 12 "12" 11 "11" 10 "10" 9 "9" 8 "8" 7 "7" 6 "6" 5 "5" 4 "4" 3 "3" 2 "2" 1 "1" 0 "Unknown" ;
VAL_ 656 DAS_LeftObj_10_Y_1_Val 321 "Error" 320 "320" 319 "319" 318 "318" 317 "317" 316 "316" 315 "315" 314 "314" 313 "313" 312 "312" 311 "311" 310 "310" 309 "309" 308 "308" 307 "307" 306 "306" 305 "305" 304 "304" 303 "303" 302 "302" 301 "301" 300 "300" 299 "299" 298 "298" 297 "297" 296 "296" 295 "295" 294 "294" 293 "293" 292 "292" 291 "291" 290 "290" 289 "289" 288 "288" 287 "287" 286 "286" 285 "285" 284 "284" 283 "283" 282 "282" 281 "281" 280 "280" 279 "279" 278 "278" 277 "277" 276 "276" 275 "275" 274 "274" 273 "273" 272 "272" 271 "271" 270 "270" 269 "269" 268 "268" 267 "267" 266 "266" 265 "265" 264 "264" 263 "263" 262 "262" 261 "261" 260 "260" 259 "259" 258 "258" 257 "257" 256 "256" 255 "255" 254 "254" 253 "253" 252 "252" 251 "251" 250 "250" 249 "249" 248 "248" 247 "247" 246 "246" 245 "245" 244 "244" 243 "243" 242 "242" 241 "241" 240 "240" 239 "239" 238 "238" 237 "237" 236 "236" 235 "235" 234 "234" 233 "233" 232 "232" 231 "231" 230 "230" 229 "229" 228 "228" 227 "227" 226 "226" 225 "225" 224 "224" 223 "223" 222 "222" 221 "221" 220 "220" 219 "219" 218 "218" 217 "217" 216 "216" 215 "215" 214 "214" 213 "213" 212 "212" 211 "211" 210 "210" 209 "209" 208 "208" 207 "207" 206 "206" 205 "205" 204 "204" 203 "203" 202 "202" 201 "201" 200 "200" 199 "199" 198 "198" 197 "197" 196 "196" 195 "195" 194 "194" 193 "193" 192 "192" 191 "191" 190 "190" 189 "189" 188 "188" 187 "187" 186 "186" 185 "185" 184 "184" 183 "183" 182 "182" 181 "181" 180 "180" 179 "179" 178 "178" 177 "177" 176 "176" 175 "175" 174 "174" 173 "173" 172 "172" 171 "171" 170 "170" 169 "169" 168 "168" 167 "167" 166 "166" 165 "165" 164 "164" 163 "163" 162 "162" 161 "161" 160 "160" 159 "159" 158 "158" 157 "157" 156 "156" 155 "155" 154 "154" 153 "153" 152 "152" 151 "151" 150 "150" 149 "149" 148 "148" 147 "147" 146 "146" 145 "145" 144 "144" 143 "143" 142 "142" 141 "141" 140 "140" 139 "139" 138 "138" 137 "137" 136 "136" 135 "135" 134 "134" 133 "133" 132 "132" 131 "131" 130 "130" 129 "129" 128 "128" 127 "127" 126 "126" 125 "125" 124 "124" 123 "123" 122 "122" 121 "121" 120 "120" 119 "119" 118 "118" 117 "117" 116 "116" 115 "115" 114 "114" 113 "113" 112 "112" 111 "111" 110 "110" 109 "109" 108 "108" 107 "107" 106 "106" 105 "105" 104 "104" 103 "103" 102 "102" 101 "101" 100 "100" 99 "99" 98 "98" 97 "97" 96 "96" 95 "95" 94 "94" 93 "93" 92 "92" 91 "91" 90 "90" 89 "89" 88 "88" 87 "87" 86 "86" 85 "85" 84 "84" 83 "83" 82 "82" 81 "81" 80 "80" 79 "79" 78 "78" 77 "77" 76 "76" 75 "75" 74 "74" 73 "73" 72 "72" 71 "71" 70 "70" 69 "69" 68 "68" 67 "67" 66 "66" 65 "65" 64 "64" 63 "63" 62 "62" 61 "61" 60 "60" 59 "59" 58 "58" 57 "57" 56 "56" 55 "55" 54 "54" 53 "53" 52 "52" 51 "51" 50 "50" 49 "49" 48 "48" 47 "47" 46 "46" 45 "45" 44 "44" 43 "43" 42 "42" 41 "41" 40 "40" 39 "39" 38 "38" 37 "37" 36 "36" 35 "35" 34 "34" 33 "33" 32 "32" 31 "31" 30 "30" 29 "29" 28 "28" 27 "27" 26 "26" 25 "25" 24 "24" 23 "23" 22 "22" 21 "21" 20 "20" 19 "19" 18 "18" 17 "17" 16 "16" 15 "15" 14 "14" 13 "13" 12 "12" 11 "11" 10 "10" 9 "9" 8 "8" 7 "7" 6 "6" 5 "5" 4 "4" 3 "3" 2 "2" 1 "1" 0 "Unknown" ;
VAL_ 656 DAS_ADBLeftLED12_Req 1 "On" 0 "Off" ;
VAL_ 656 DAS_ADBLeftLED18_Req 1 "On" 0 "Off" ;
VAL_ 656 DAS_LeftObj_3_Z_1_Val 81 "Error" 80 "80" 79 "79" 78 "78" 77 "77" 76 "76" 75 "75" 74 "74" 73 "73" 72 "72" 71 "71" 70 "70" 69 "69" 68 "68" 67 "67" 66 "66" 65 "65" 64 "64" 63 "63" 62 "62" 61 "61" 60 "60" 59 "59" 58 "58" 57 "57" 56 "56" 55 "55" 54 "54" 53 "53" 52 "52" 51 "51" 50 "50" 49 "49" 48 "48" 47 "47" 46 "46" 45 "45" 44 "44" 43 "43" 42 "42" 41 "41" 40 "40" 39 "39" 38 "38" 37 "37" 36 "36" 35 "35" 34 "34" 33 "33" 32 "32" 31 "31" 30 "30" 29 "29" 28 "28" 27 "27" 26 "26" 25 "25" 24 "24" 23 "23" 22 "22" 21 "21" 20 "20" 19 "19" 18 "18" 17 "17" 16 "16" 15 "15" 14 "14" 13 "13" 12 "12" 11 "11" 10 "10" 9 "9" 8 "8" 7 "7" 6 "6" 5 "5" 4 "4" 3 "3" 2 "2" 1 "1" 0 "Unknown" ;
VAL_ 656 DAS_LeftObj_2_Y_1_Val 321 "Error" 320 "320" 319 "319" 318 "318" 317 "317" 316 "316" 315 "315" 314 "314" 313 "313" 312 "312" 311 "311" 310 "310" 309 "309" 308 "308" 307 "307" 306 "306" 305 "305" 304 "304" 303 "303" 302 "302" 301 "301" 300 "300" 299 "299" 298 "298" 297 "297" 296 "296" 295 "295" 294 "294" 293 "293" 292 "292" 291 "291" 290 "290" 289 "289" 288 "288" 287 "287" 286 "286" 285 "285" 284 "284" 283 "283" 282 "282" 281 "281" 280 "280" 279 "279" 278 "278" 277 "277" 276 "276" 275 "275" 274 "274" 273 "273" 272 "272" 271 "271" 270 "270" 269 "269" 268 "268" 267 "267" 266 "266" 265 "265" 264 "264" 263 "263" 262 "262" 261 "261" 260 "260" 259 "259" 258 "258" 257 "257" 256 "256" 255 "255" 254 "254" 253 "253" 252 "252" 251 "251" 250 "250" 249 "249" 248 "248" 247 "247" 246 "246" 245 "245" 244 "244" 243 "243" 242 "242" 241 "241" 240 "240" 239 "239" 238 "238" 237 "237" 236 "236" 235 "235" 234 "234" 233 "233" 232 "232" 231 "231" 230 "230" 229 "229" 228 "228" 227 "227" 226 "226" 225 "225" 224 "224" 223 "223" 222 "222" 221 "221" 220 "220" 219 "219" 218 "218" 217 "217" 216 "216" 215 "215" 214 "214" 213 "213" 212 "212" 211 "211" 210 "210" 209 "209" 208 "208" 207 "207" 206 "206" 205 "205" 204 "204" 203 "203" 202 "202" 201 "201" 200 "200" 199 "199" 198 "198" 197 "197" 196 "196" 195 "195" 194 "194" 193 "193" 192 "192" 191 "191" 190 "190" 189 "189" 188 "188" 187 "187" 186 "186" 185 "185" 184 "184" 183 "183" 182 "182" 181 "181" 180 "180" 179 "179" 178 "178" 177 "177" 176 "176" 175 "175" 174 "174" 173 "173" 172 "172" 171 "171" 170 "170" 169 "169" 168 "168" 167 "167" 166 "166" 165 "165" 164 "164" 163 "163" 162 "162" 161 "161" 160 "160" 159 "159" 158 "158" 157 "157" 156 "156" 155 "155" 154 "154" 153 "153" 152 "152" 151 "151" 150 "150" 149 "149" 148 "148" 147 "147" 146 "146" 145 "145" 144 "144" 143 "143" 142 "142" 141 "141" 140 "140" 139 "139" 138 "138" 137 "137" 136 "136" 135 "135" 134 "134" 133 "133" 132 "132" 131 "131" 130 "130" 129 "129" 128 "128" 127 "127" 126 "126" 125 "125" 124 "124" 123 "123" 122 "122" 121 "121" 120 "120" 119 "119" 118 "118" 117 "117" 116 "116" 115 "115" 114 "114" 113 "113" 112 "112" 111 "111" 110 "110" 109 "109" 108 "108" 107 "107" 106 "106" 105 "105" 104 "104" 103 "103" 102 "102" 101 "101" 100 "100" 99 "99" 98 "98" 97 "97" 96 "96" 95 "95" 94 "94" 93 "93" 92 "92" 91 "91" 90 "90" 89 "89" 88 "88" 87 "87" 86 "86" 85 "85" 84 "84" 83 "83" 82 "82" 81 "81" 80 "80" 79 "79" 78 "78" 77 "77" 76 "76" 75 "75" 74 "74" 73 "73" 72 "72" 71 "71" 70 "70" 69 "69" 68 "68" 67 "67" 66 "66" 65 "65" 64 "64" 63 "63" 62 "62" 61 "61" 60 "60" 59 "59" 58 "58" 57 "57" 56 "56" 55 "55" 54 "54" 53 "53" 52 "52" 51 "51" 50 "50" 49 "49" 48 "48" 47 "47" 46 "46" 45 "45" 44 "44" 43 "43" 42 "42" 41 "41" 40 "40" 39 "39" 38 "38" 37 "37" 36 "36" 35 "35" 34 "34" 33 "33" 32 "32" 31 "31" 30 "30" 29 "29" 28 "28" 27 "27" 26 "26" 25 "25" 24 "24" 23 "23" 22 "22" 21 "21" 20 "20" 19 "19" 18 "18" 17 "17" 16 "16" 15 "15" 14 "14" 13 "13" 12 "12" 11 "11" 10 "10" 9 "9" 8 "8" 7 "7" 6 "6" 5 "5" 4 "4" 3 "3" 2 "2" 1 "1" 0 "Unknown" ;
VAL_ 656 DAS_ADBLeftLED17_Req 1 "On" 0 "Off" ;
VAL_ 656 DAS_LeftObj_9_Z_1_Val 81 "Error" 80 "80" 79 "79" 78 "78" 77 "77" 76 "76" 75 "75" 74 "74" 73 "73" 72 "72" 71 "71" 70 "70" 69 "69" 68 "68" 67 "67" 66 "66" 65 "65" 64 "64" 63 "63" 62 "62" 61 "61" 60 "60" 59 "59" 58 "58" 57 "57" 56 "56" 55 "55" 54 "54" 53 "53" 52 "52" 51 "51" 50 "50" 49 "49" 48 "48" 47 "47" 46 "46" 45 "45" 44 "44" 43 "43" 42 "42" 41 "41" 40 "40" 39 "39" 38 "38" 37 "37" 36 "36" 35 "35" 34 "34" 33 "33" 32 "32" 31 "31" 30 "30" 29 "29" 28 "28" 27 "27" 26 "26" 25 "25" 24 "24" 23 "23" 22 "22" 21 "21" 20 "20" 19 "19" 18 "18" 17 "17" 16 "16" 15 "15" 14 "14" 13 "13" 12 "12" 11 "11" 10 "10" 9 "9" 8 "8" 7 "7" 6 "6" 5 "5" 4 "4" 3 "3" 2 "2" 1 "1" 0 "Unknown" ;
VAL_ 656 DAS_LeftObj_1_Z_1_Val 81 "Error" 80 "80" 79 "79" 78 "78" 77 "77" 76 "76" 75 "75" 74 "74" 73 "73" 72 "72" 71 "71" 70 "70" 69 "69" 68 "68" 67 "67" 66 "66" 65 "65" 64 "64" 63 "63" 62 "62" 61 "61" 60 "60" 59 "59" 58 "58" 57 "57" 56 "56" 55 "55" 54 "54" 53 "53" 52 "52" 51 "51" 50 "50" 49 "49" 48 "48" 47 "47" 46 "46" 45 "45" 44 "44" 43 "43" 42 "42" 41 "41" 40 "40" 39 "39" 38 "38" 37 "37" 36 "36" 35 "35" 34 "34" 33 "33" 32 "32" 31 "31" 30 "30" 29 "29" 28 "28" 27 "27" 26 "26" 25 "25" 24 "24" 23 "23" 22 "22" 21 "21" 20 "20" 19 "19" 18 "18" 17 "17" 16 "16" 15 "15" 14 "14" 13 "13" 12 "12" 11 "11" 10 "10" 9 "9" 8 "8" 7 "7" 6 "6" 5 "5" 4 "4" 3 "3" 2 "2" 1 "1" 0 "Unknown" ;
VAL_ 656 DAS_ADBLeftLED9_Req 1 "On" 0 "Off" ;
VAL_ 656 DAS_ADBLeftLED4_Req 1 "On" 0 "Off" ;
VAL_ 656 DAS_LeftObj_7_Y_1_Val 321 "Error" 320 "320" 319 "319" 318 "318" 317 "317" 316 "316" 315 "315" 314 "314" 313 "313" 312 "312" 311 "311" 310 "310" 309 "309" 308 "308" 307 "307" 306 "306" 305 "305" 304 "304" 303 "303" 302 "302" 301 "301" 300 "300" 299 "299" 298 "298" 297 "297" 296 "296" 295 "295" 294 "294" 293 "293" 292 "292" 291 "291" 290 "290" 289 "289" 288 "288" 287 "287" 286 "286" 285 "285" 284 "284" 283 "283" 282 "282" 281 "281" 280 "280" 279 "279" 278 "278" 277 "277" 276 "276" 275 "275" 274 "274" 273 "273" 272 "272" 271 "271" 270 "270" 269 "269" 268 "268" 267 "267" 266 "266" 265 "265" 264 "264" 263 "263" 262 "262" 261 "261" 260 "260" 259 "259" 258 "258" 257 "257" 256 "256" 255 "255" 254 "254" 253 "253" 252 "252" 251 "251" 250 "250" 249 "249" 248 "248" 247 "247" 246 "246" 245 "245" 244 "244" 243 "243" 242 "242" 241 "241" 240 "240" 239 "239" 238 "238" 237 "237" 236 "236" 235 "235" 234 "234" 233 "233" 232 "232" 231 "231" 230 "230" 229 "229" 228 "228" 227 "227" 226 "226" 225 "225" 224 "224" 223 "223" 222 "222" 221 "221" 220 "220" 219 "219" 218 "218" 217 "217" 216 "216" 215 "215" 214 "214" 213 "213" 212 "212" 211 "211" 210 "210" 209 "209" 208 "208" 207 "207" 206 "206" 205 "205" 204 "204" 203 "203" 202 "202" 201 "201" 200 "200" 199 "199" 198 "198" 197 "197" 196 "196" 195 "195" 194 "194" 193 "193" 192 "192" 191 "191" 190 "190" 189 "189" 188 "188" 187 "187" 186 "186" 185 "185" 184 "184" 183 "183" 182 "182" 181 "181" 180 "180" 179 "179" 178 "178" 177 "177" 176 "176" 175 "175" 174 "174" 173 "173" 172 "172" 171 "171" 170 "170" 169 "169" 168 "168" 167 "167" 166 "166" 165 "165" 164 "164" 163 "163" 162 "162" 161 "161" 160 "160" 159 "159" 158 "158" 157 "157" 156 "156" 155 "155" 154 "154" 153 "153" 152 "152" 151 "151" 150 "150" 149 "149" 148 "148" 147 "147" 146 "146" 145 "145" 144 "144" 143 "143" 142 "142" 141 "141" 140 "140" 139 "139" 138 "138" 137 "137" 136 "136" 135 "135" 134 "134" 133 "133" 132 "132" 131 "131" 130 "130" 129 "129" 128 "128" 127 "127" 126 "126" 125 "125" 124 "124" 123 "123" 122 "122" 121 "121" 120 "120" 119 "119" 118 "118" 117 "117" 116 "116" 115 "115" 114 "114" 113 "113" 112 "112" 111 "111" 110 "110" 109 "109" 108 "108" 107 "107" 106 "106" 105 "105" 104 "104" 103 "103" 102 "102" 101 "101" 100 "100" 99 "99" 98 "98" 97 "97" 96 "96" 95 "95" 94 "94" 93 "93" 92 "92" 91 "91" 90 "90" 89 "89" 88 "88" 87 "87" 86 "86" 85 "85" 84 "84" 83 "83" 82 "82" 81 "81" 80 "80" 79 "79" 78 "78" 77 "77" 76 "76" 75 "75" 74 "74" 73 "73" 72 "72" 71 "71" 70 "70" 69 "69" 68 "68" 67 "67" 66 "66" 65 "65" 64 "64" 63 "63" 62 "62" 61 "61" 60 "60" 59 "59" 58 "58" 57 "57" 56 "56" 55 "55" 54 "54" 53 "53" 52 "52" 51 "51" 50 "50" 49 "49" 48 "48" 47 "47" 46 "46" 45 "45" 44 "44" 43 "43" 42 "42" 41 "41" 40 "40" 39 "39" 38 "38" 37 "37" 36 "36" 35 "35" 34 "34" 33 "33" 32 "32" 31 "31" 30 "30" 29 "29" 28 "28" 27 "27" 26 "26" 25 "25" 24 "24" 23 "23" 22 "22" 21 "21" 20 "20" 19 "19" 18 "18" 17 "17" 16 "16" 15 "15" 14 "14" 13 "13" 12 "12" 11 "11" 10 "10" 9 "9" 8 "8" 7 "7" 6 "6" 5 "5" 4 "4" 3 "3" 2 "2" 1 "1" 0 "Unknown" ;
VAL_ 785 CCU_AirDirectionFR_Foot_Stat 1 "Active" 0 "Inactive" ;
VAL_ 785 CCU_AirDirectionFR_Face_Stat 1 "Active" 0 "Inactive" ;
VAL_ 785 CCU_AirDirectionFR_Def_Stat 1 "Active" 0 "Inactive" ;
VAL_ 785 CCU_AirDirectionFL_Foot_Stat 1 "Active" 0 "Inactive" ;
VAL_ 785 CCU_AirDirectionFL_Face_Stat 1 "Active" 0 "Inactive" ;
VAL_ 785 CCU_AirDirectionRL_Foot_Stat 1 "Active" 0 "Inactive" ;
VAL_ 785 CCU_ModeRL_Stat 2 "Semi-auto mode is active" 1 "Auto mode is active" 0 "Manual mode is active" ;
VAL_ 785 CCU_AutoModeRR_Stat 5 "Auto mode 5 is active" 4 "Auto mode 4 is active" 3 "Auto mode 3 is active" 2 "Auto mode 2 is active" 1 "Auto mode 1 is active" 0 "Auto mode is inactive" ;
VAL_ 785 CCU_AutoModeFR_Stat 5 "Auto mode 5 is active" 4 "Auto mode 4 is active" 3 "Auto mode 3 is active" 2 "Auto mode 2 is active" 1 "Auto mode 1 is active" 0 "Auto mode is inactive" ;
VAL_ 785 CCU_AirDirectionRR_Face_Stat 1 "Active" 0 "Inactive" ;
VAL_ 785 CCU_ModeRR_Stat 2 "Semi-auto mode is active" 1 "Auto mode is active" 0 "Manual mode is active" ;
VAL_ 785 CCU_AirDirectionRR_Foot_Stat 1 "Active" 0 "Inactive" ;
VAL_ 785 CCU_Recirculation_Stat 2 "Auto recirculation mode" 1 "Recirculation mode (Rec on)" 0 "Fresh air mode (Rec off)" ;
VAL_ 785 CCU_AutoModeRL_Stat 5 "Auto mode 5 is active" 4 "Auto mode 4 is active" 3 "Auto mode 3 is active" 2 "Auto mode 2 is active" 1 "Auto mode 1 is active" 0 "Auto mode is inactive" ;
VAL_ 785 CCU_AirDirectionFL_Def_Stat 1 "Active" 0 "Inactive" ;
VAL_ 785 CCU_AutoModeFL_Stat 5 "Auto mode 5 is active" 4 "Auto mode 4 is active" 3 "Auto mode 3 is active" 2 "Auto mode 2 is active" 1 "Auto mode 1 is active" 0 "Auto mode is inactive" ;
VAL_ 785 CCU_ModeFL_Stat 2 "Semi-auto mode is active" 1 "Auto mode is active" 0 "Manual mode is active" ;
VAL_ 785 CCU_ModeFR_Stat 2 "Semi-auto mode is active" 1 "Auto mode is active" 0 "Manual mode is active" ;
VAL_ 785 CCU_AirDirectionRL_Face_Stat 1 "Active" 0 "Inactive" ;
VAL_ 785 CCU_BlowerSpeedRL_Stat 7 "7 step" 6 "6 step" 5 "5 step" 4 "4 step" 3 "3 step" 2 "2 step" 1 "1 step" 0 "Blower off" ;
VAL_ 785 CCU_BlowerSpeedFR_Stat 7 "7 step" 6 "6 step" 5 "5 step" 4 "4 step" 3 "3 step" 2 "2 step" 1 "1 step" 0 "Blower off" ;
VAL_ 785 CCU_BlowerSpeedFL_Stat 7 "7 step" 6 "6 step" 5 "5 step" 4 "4 step" 3 "3 step" 2 "2 step" 1 "1 step" 0 "Blower off" ;
VAL_ 785 CCU_BlowerSpeedRR_Stat 7 "7 step" 6 "6 step" 5 "5 step" 4 "4 step" 3 "3 step" 2 "2 step" 1 "1 step" 0 "Blower off" ;
VAL_ 560 BCM_TargetLvlALS_Req 255 "Reserved" 127 "Zero level" 0 "No change" ;
VAL_ 560 BCM_CorneringLight_Req 3 "On both sides" 2 "On right side" 1 "On left side" 0 "Off" ;
VAL_ 560 BCM_RearFogLightCntrl_Req 1 "On" 0 "Off" ;
VAL_ 560 BCM_PositionLightRear_Req 1 "On" 0 "Off" ;
VAL_ 560 BCM_HighBeam_Req 3 "On boost" 2 "On auto" 1 "On manual" 0 "Off" ;
VAL_ 560 BCM_ELSStat_Req 1 "On" 0 "Off" ;
VAL_ 560 BCM_ReverseLightCntrl_Req 1 "On" 0 "Off" ;
VAL_ 560 BCM_CourtesyLightEffect_Req 2 "Started leaving" 1 "Started welcome" 0 "Off" ;
VAL_ 560 BCM_TurnIndL_Req 1 "On" 0 "Off" ;
VAL_ 560 BCM_TrafficSide_Req 1 "Right-Hand" 0 "Left-Hand" ;
VAL_ 560 BCM_CourtesyProjAnimation_Req 3 "Reserved" 2 "Started leaving" 1 "Started welcome" 0 "Off" ;
VAL_ 560 BCM_DayRunningLight_Req 1 "On" 0 "Off" ;
VAL_ 560 BCM_LowBeam_Req 4 "On W mode" 3 "On E mode" 2 "On V mode" 1 "On C mode" 0 "Off" ;
VAL_ 560 BCM_PositionLightFront_Req 1 "On" 0 "Off" ;
VAL_ 560 BCM_SteeringWheelAngle_Val 40 "10 and more degrees right" 39 "9.5 degrees right" 38 "9 degrees right" 37 "8.5 degrees right" 36 "8 degrees right" 35 "7.5 degrees right" 34 "7 degrees right" 33 "6.5 degrees right" 32 "6 degrees right" 31 "5.5 degrees right" 30 "5 degrees right" 29 "4.5 degrees right" 28 "4 degrees right" 27 "3.5 degrees right" 26 "3 degrees right" 25 "2.5 degrees right" 24 "2 degrees right" 23 "1.5 degrees right" 22 "1 degrees right" 21 "0.5 degrees right" 20 "Zero position" 19 "0.5 degrees left" 18 "1 degrees left" 17 "1.5 degrees left" 16 "2 degrees left" 15 "2.5 degrees left" 14 "3 degrees left" 13 "3.5 degrees left" 12 "4 degrees left" 11 "4.5 degrees left" 10 "5 degrees left" 9 "5.5 degrees left" 8 "6 degrees left" 7 "6.5 degrees left" 6 "7 degrees left" 5 "7.5 degrees left" 4 "8 degrees left" 3 "8.5 degrees left" 2 "9 degrees left" 1 "9.5 degrees left" 0 "10 and more degrees left" ;
VAL_ 560 BCM_BrakeLightCntrl_Req 1 "On" 0 "Off" ;
VAL_ 560 BCM_TurnIndR_Req 1 "On" 0 "Off" ;
VAL_ 560 BCM_MLIA_Start_Req 1 "MLIA Start Request" 0 "No Request" ;
VAL_ 560 BCM_Proj_Start_Req 1 "Projection Start Request" 0 "No request" ;
VAL_ 1306 VIN_Addressing 2 "VIN Part 3" 1 "VIN Part 2" 0 "VIN Part 1" ;
VAL_ 131 DAS_CcLimState_Stat 1 "Active" 0 "Off" ;
VAL_ 131 DAS_CcEngagement_Stat 3 "MAS" 2 "LIM" 1 "CC/ACC" 0 "Nothing" ;
VAL_ 131 DAS_CcMotIncFlag_Stat 1 "Requested" 0 "Not requested" ;
VAL_ 357 DAS_TmissionChange_Req 4 "D" 3 "N" 2 "R" 1 "P" 0 "Not requested" ;
VAL_ 357 DAS_CcVcuState_Stat 1 "Active" 0 "Off or error" ;
VAL_ 357 DAS_CcVcuMotIncFlag_Stat 1 "Requested" 0 "Not requested" ;
VAL_ 357 DAS_CcVcuEngagement_Stat 3 "Small torque (Auto Parking)" 2 "Torque is limited (Lim)" 1 "Torque is executing (CC, AEB ect)" 0 "Nothing" ;
